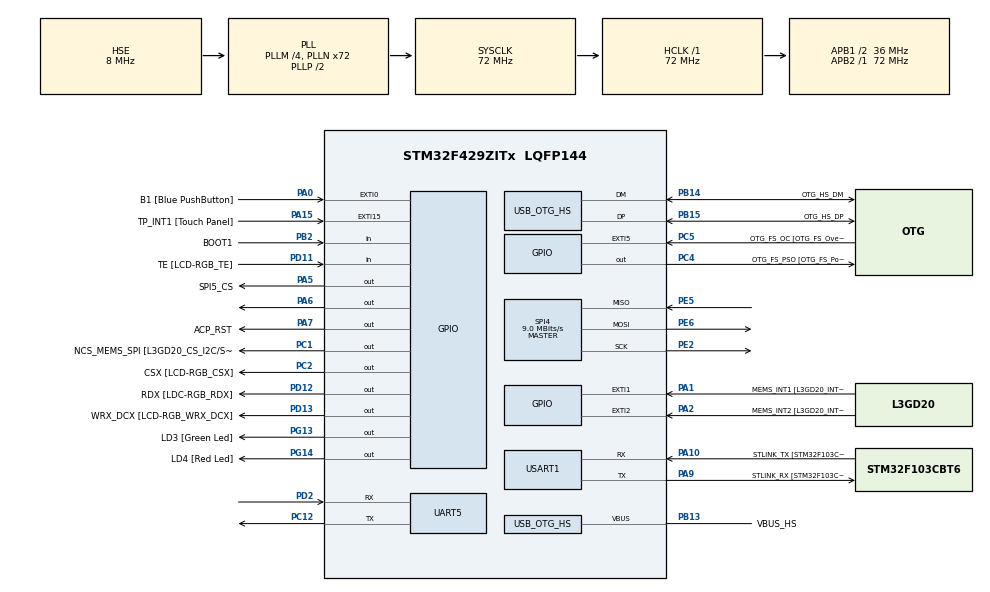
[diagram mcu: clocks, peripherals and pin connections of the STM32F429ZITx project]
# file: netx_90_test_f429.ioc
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Mcu.Family=STM32F4
Mcu.Name=STM32F429ZITx
Mcu.Package=LQFP144
NVIC.OTG_HS_IRQn=true\:0\:0\:false\:false\:true\:true\:true\:true
NVIC.PriorityGroup=NVIC_PRIORITYGROUP_4
NVIC.SPI4_IRQn=true\:0\:0\:false\:false\:true\:true\:true\:true
NVIC.TIM3_IRQn=true\:0\:0\:false\:false\:true\:true\:true\:true
NVIC.TIM6_DAC_IRQn=true\:15\:0\:false\:false\:true\:false\:true\:true
NVIC.TimeBase=TIM6_DAC_IRQn
NVIC.TimeBaseIP=TIM6
NVIC.UART5_IRQn=true\:0\:0\:false\:false\:true\:true\:true\:true
PA0/WKUP.GPIO_Label=B1 [Blue PushButton]
PA0/WKUP.GPIO_ModeDefaultEXTI=GPIO_MODE_EVT_RISING
PA0/WKUP.GPIO_PuPd=GPIO_NOPULL
PA0/WKUP.Signal=GPXTI0
PA1.GPIO_Label=MEMS_INT1 [L3GD20_INT1]
PA1.GPIO_ModeDefaultEXTI=GPIO_MODE_EVT_RISING
PA1.GPIO_PuPd=GPIO_NOPULL
PA1.Signal=GPXTI1
PA10.GPIO_Label=STLINK_TX [STM32F103CBT6_PA2]
PA10.Mode=Asynchronous
PA10.Signal=USART1_RX
PA11.GPIO_Label=R4
PA11.GPIO_Mode=GPIO_MODE_AF_PP
PA11.GPIO_PuPd=GPIO_NOPULL
PA11.GPIO_Speed=GPIO_SPEED_FREQ_LOW
PA11.Signal=LTDC_R4
PA12.GPIO_Label=R5
PA12.GPIO_Mode=GPIO_MODE_AF_PP
PA12.GPIO_PuPd=GPIO_NOPULL
PA12.GPIO_Speed=GPIO_SPEED_FREQ_LOW
PA12.Signal=LTDC_R5
PA13.GPIO_Label=SWDIO
PA13.Mode=Serial_Wire
PA13.Signal=SYS_JTMS-SWDIO
PA14.GPIO_Label=SWCLK
PA14.Mode=Serial_Wire
PA14.Signal=SYS_JTCK-SWCLK
PA15.GPIO_Label=TP_INT1 [Touch Panel]
PA15.GPIO_ModeDefaultEXTI=GPIO_MODE_EVT_RISING
PA15.GPIO_PuPd=GPIO_NOPULL
PA15.Signal=GPXTI15
PA2.GPIO_Label=MEMS_INT2 [L3GD20_INT2]
PA2.GPIO_ModeDefaultEXTI=GPIO_MODE_EVT_RISING
PA2.GPIO_PuPd=GPIO_NOPULL
PA2.Signal=GPXTI2
PA3.GPIO_Label=B5
PA3.GPIO_Mode=GPIO_MODE_AF_PP
PA3.GPIO_PuPd=GPIO_NOPULL
PA3.GPIO_Speed=GPIO_SPEED_FREQ_LOW
PA3.Signal=LTDC_B5
PA4.GPIO_Label=VSYNC
PA4.GPIO_Mode=GPIO_MODE_AF_PP
PA4.GPIO_PuPd=GPIO_NOPULL
PA4.GPIO_Speed=GPIO_SPEED_FREQ_LOW
PA4.Signal=LTDC_VSYNC
PA5.GPIO_Label=SPI5_CS
PA5.Signal=GPIO_Output
PA6.Signal=GPIO_Output
PA7.GPIO_Label=ACP_RST
PA7.GPIO_Mode=GPIO_MODE_OUTPUT_PP
PA7.GPIO_PuPd=GPIO_NOPULL
PA7.GPIO_Speed=GPIO_SPEED_FREQ_LOW
PA7.Signal=GPIO_Output
PA8.GPIO_Label=I2C3_SCL [ACP/RF_SCL]
PA8.GPIO_Mode=GPIO_MODE_AF_OD
PA8.GPIO_Pu=GPIO_PULLUP
PA8.GPIO_PuPd=GPIO_NOPULL
PA8.GPIO_Speed=GPIO_SPEED_FREQ_LOW
PA8.Signal=I2C3_SCL
PA9.GPIO_Label=STLINK_RX [STM32F103CBT6_PA3]
PA9.Mode=Asynchronous
PA9.Signal=USART1_TX
PB0.GPIO_Label=R3
PB0.GPIO_Mode=GPIO_MODE_AF_PP
PB0.GPIO_PuPd=GPIO_NOPULL
PB0.GPIO_Speed=GPIO_SPEED_FREQ_LOW
PB0.Signal=LTDC_R3
PB1.GPIO_Label=R6
PB1.GPIO_Mode=GPIO_MODE_AF_PP
PB1.GPIO_PuPd=GPIO_NOPULL
PB1.GPIO_Speed=GPIO_SPEED_FREQ_LOW
PB1.Signal=LTDC_R6
PB10.GPIO_Label=G4
PB10.GPIO_Mode=GPIO_MODE_AF_PP
PB10.GPIO_PuPd=GPIO_NOPULL
PB10.GPIO_Speed=GPIO_SPEED_FREQ_LOW
PB10.Signal=LTDC_G4
PB11.GPIO_Label=G5
PB11.GPIO_Mode=GPIO_MODE_AF_PP
PB11.GPIO_PuPd=GPIO_NOPULL
PB11.GPIO_Speed=GPIO_SPEED_FREQ_LOW
PB11.Signal=LTDC_G5
PB12.GPIO_Label=OTG_HS_ID
PB12.GPIO_Mode=GPIO_MODE_AF_PP
PB12.GPIO_PuPd=GPIO_NOPULL
PB12.GPIO_Speed=GPIO_SPEED_FREQ_LOW
PB12.Signal=USB_OTG_HS_ID
PB13.GPIO_Label=VBUS_HS
PB13.GPIO_Mode=GPIO_MODE_INPUT
PB13.GPIO_PuPd=GPIO_NOPULL
PB13.Mode=Activate_VBUS_FS
PB13.Signal=USB_OTG_HS_VBUS
PB14.GPIO_Label=OTG_HS_DM
PB14.GPIO_Mode=GPIO_MODE_AF_PP
PB14.GPIO_PuPd=GPIO_NOPULL
PB14.GPIO_Speed=GPIO_SPEED_FREQ_LOW
PB14.Mode=Host_FS
PB14.Signal=USB_OTG_HS_DM
PB15.GPIO_Label=OTG_HS_DP
PB15.GPIO_Mode=GPIO_MODE_AF_PP
PB15.GPIO_PuPd=GPIO_NOPULL
PB15.GPIO_Speed=GPIO_SPEED_FREQ_LOW
PB15.Mode=Host_FS
PB15.Signal=USB_OTG_HS_DP
PB2/BOOT1.GPIO_Label=BOOT1
PB2/BOOT1.GPIO_Mode=GPIO_MODE_INPUT
PB2/BOOT1.GPIO_PuPd=GPIO_NOPULL
PB2/BOOT1.Signal=GPIO_Input
PB5.GPIO_Label=SDCKE1
PB5.GPIO_Mode=GPIO_MODE_AF_PP
PB5.GPIO_PuPd=GPIO_NOPULL
PB5.GPIO_Speed=GPIO_SPEED_FREQ_VERY_HIGH
PB5.Signal=FMC_SDCKE1
PB6.GPIO_Label=SDNE1 [SDRAM_CS]
PB6.GPIO_Mode=GPIO_MODE_AF_PP
PB6.GPIO_PuPd=GPIO_NOPULL
PB6.GPIO_Speed=GPIO_SPEED_FREQ_VERY_HIGH
PB6.Signal=FMC_SDNE1
PB8.GPIO_Label=B6
PB8.GPIO_Mode=GPIO_MODE_AF_PP
PB8.GPIO_PuPd=GPIO_NOPULL
PB8.GPIO_Speed=GPIO_SPEED_FREQ_LOW
PB8.Signal=LTDC_B6
PB9.GPIO_Label=B7
PB9.GPIO_Mode=GPIO_MODE_AF_PP
PB9.GPIO_PuPd=GPIO_NOPULL
PB9.GPIO_Speed=GPIO_SPEED_FREQ_LOW
PB9.Signal=LTDC_B7
PC0.GPIO_Label=SDNWE
PC0.GPIO_Mode=GPIO_MODE_AF_PP
PC0.GPIO_PuPd=GPIO_NOPULL
PC0.GPIO_Speed=GPIO_SPEED_FREQ_VERY_HIGH
PC0.Signal=FMC_SDNWE
PC1.GPIO_Label=NCS_MEMS_SPI [L3GD20_CS_I2C/SPI]
PC1.GPIO_Mode=GPIO_MODE_OUTPUT_PP
PC1.GPIO_PuPd=GPIO_NOPULL
PC1.GPIO_Speed=GPIO_SPEED_FREQ_LOW
PC1.Signal=GPIO_Output
PC10.GPIO_Label=R2
PC10.GPIO_Mode=GPIO_MODE_AF_PP
PC10.GPIO_PuPd=GPIO_NOPULL
PC10.GPIO_Speed=GPIO_SPEED_FREQ_LOW
PC10.Signal=LTDC_R2
PC12.Mode=Asynchronous
PC12.Signal=UART5_TX
PC14/OSC32_IN.GPIO_Label=PC14-OSC32_IN
PC14/OSC32_IN.Signal=RCC_OSC32_IN
PC15/OSC32_OUT.GPIO_Label=PC15-OSC32_OUT
PC15/OSC32_OUT.Signal=RCC_OSC32_OUT
PC2.GPIO_Label=CSX [LCD-RGB_CSX]
PC2.GPIO_Mode=GPIO_MODE_OUTPUT_PP
PC2.GPIO_PuPd=GPIO_NOPULL
PC2.GPIO_Speed=GPIO_SPEED_FREQ_LOW
PC2.Signal=GPIO_Output
PC4.GPIO_Label=OTG_FS_PSO [OTG_FS_PowerSwitchOn]
PC4.GPIO_Mode=GPIO_MODE_OUTPUT_PP
PC4.GPIO_PuPd=GPIO_NOPULL
PC4.GPIO_Speed=GPIO_SPEED_FREQ_LOW
PC4.Signal=GPIO_Output
PC5.GPIO_Label=OTG_FS_OC [OTG_FS_OverCurrent]
PC5.GPIO_ModeDefaultEXTI=GPIO_MODE_EVT_RISING
PC5.Signal=GPXTI5
PC6.GPIO_Label=HSYNC
PC6.GPIO_Mode=GPIO_MODE_AF_PP
PC6.GPIO_PuPd=GPIO_NOPULL
PC6.GPIO_Speed=GPIO_SPEED_FREQ_LOW
PC6.Signal=LTDC_HSYNC
PC7.GPIO_Label=G6
PC7.GPIO_Mode=GPIO_MODE_AF_PP
PC7.GPIO_PuPd=GPIO_NOPULL
PC7.GPIO_Speed=GPIO_SPEED_FREQ_LOW
PC7.Signal=LTDC_G6
PC9.GPIO_Label=I2C3_SDA [ACP/RF_SDA]
PC9.GPIO_Mode=GPIO_MODE_AF_OD
PC9.GPIO_Pu=GPIO_PULLUP
PC9.GPIO_PuPd=GPIO_NOPULL
PC9.GPIO_Speed=GPIO_SPEED_FREQ_LOW
PC9.Signal=I2C3_SDA
PD0.GPIO_Label=D2
PD0.GPIO_Mode=GPIO_MODE_AF_PP
PD0.GPIO_PuPd=GPIO_NOPULL
PD0.GPIO_Speed=GPIO_SPEED_FREQ_VERY_HIGH
PD0.Signal=FMC_D2_DA2
PD1.GPIO_Label=D3
PD1.GPIO_Mode=GPIO_MODE_AF_PP
PD1.GPIO_PuPd=GPIO_NOPULL
PD1.GPIO_Speed=GPIO_SPEED_FREQ_VERY_HIGH
PD1.Signal=FMC_D3_DA3
PD10.GPIO_Label=D15
PD10.GPIO_Mode=GPIO_MODE_AF_PP
PD10.GPIO_PuPd=GPIO_NOPULL
PD10.GPIO_Speed=GPIO_SPEED_FREQ_VERY_HIGH
PD10.Signal=FMC_D15_DA15
PD11.GPIO_Label=TE [LCD-RGB_TE]
PD11.GPIO_Mode=GPIO_MODE_INPUT
PD11.GPIO_PuPd=GPIO_NOPULL
PD11.Signal=GPIO_Input
PD12.GPIO_Label=RDX [LDC-RGB_RDX]
PD12.GPIO_Mode=GPIO_MODE_OUTPUT_PP
PD12.GPIO_PuPd=GPIO_NOPULL
PD12.GPIO_Speed=GPIO_SPEED_FREQ_LOW
PD12.Signal=GPIO_Output
PD13.GPIO_Label=WRX_DCX [LCD-RGB_WRX_DCX]
PD13.GPIO_Mode=GPIO_MODE_OUTPUT_PP
PD13.GPIO_PuPd=GPIO_NOPULL
PD13.GPIO_Speed=GPIO_SPEED_FREQ_LOW
PD13.Signal=GPIO_Output
PD14.GPIO_Label=D0
PD14.GPIO_Mode=GPIO_MODE_AF_PP
PD14.GPIO_PuPd=GPIO_NOPULL
PD14.GPIO_Speed=GPIO_SPEED_FREQ_VERY_HIGH
PD14.Signal=FMC_D0_DA0
PD15.GPIO_Label=D1
PD15.GPIO_Mode=GPIO_MODE_AF_PP
PD15.GPIO_PuPd=GPIO_NOPULL
PD15.GPIO_Speed=GPIO_SPEED_FREQ_VERY_HIGH
PD15.Signal=FMC_D1_DA1
PD2.Mode=Asynchronous
PD2.Signal=UART5_RX
PD3.GPIO_Label=G7
PD3.GPIO_Mode=GPIO_MODE_AF_PP
PD3.GPIO_PuPd=GPIO_NOPULL
PD3.GPIO_Speed=GPIO_SPEED_FREQ_LOW
PD3.Signal=LTDC_G7
PD6.GPIO_Label=B2
PD6.GPIO_Mode=GPIO_MODE_AF_PP
PD6.GPIO_PuPd=GPIO_NOPULL
PD6.GPIO_Speed=GPIO_SPEED_FREQ_LOW
PD6.Signal=LTDC_B2
PD8.GPIO_Label=D13
PD8.GPIO_Mode=GPIO_MODE_AF_PP
PD8.GPIO_PuPd=GPIO_NOPULL
PD8.GPIO_Speed=GPIO_SPEED_FREQ_VERY_HIGH
PD8.Signal=FMC_D13_DA13
PD9.GPIO_Label=D14
PD9.GPIO_Mode=GPIO_MODE_AF_PP
PD9.GPIO_PuPd=GPIO_NOPULL
PD9.GPIO_Speed=GPIO_SPEED_FREQ_VERY_HIGH
PD9.Signal=FMC_D14_DA14
PE0.GPIO_Label=NBL0 [SDRAM_LDQM]
PE0.GPIO_Mode=GPIO_MODE_AF_PP
PE0.GPIO_PuPd=GPIO_NOPULL
PE0.GPIO_Speed=GPIO_SPEED_FREQ_VERY_HIGH
PE0.Signal=FMC_NBL0
PE1.GPIO_Label=NBL1 [SDRAM_UDQM]
PE1.GPIO_Mode=GPIO_MODE_AF_PP
PE1.GPIO_PuPd=GPIO_NOPULL
PE1.GPIO_Speed=GPIO_SPEED_FREQ_VERY_HIGH
PE1.Signal=FMC_NBL1
PE10.GPIO_Label=D7
PE10.GPIO_Mode=GPIO_MODE_AF_PP
PE10.GPIO_PuPd=GPIO_NOPULL
PE10.GPIO_Speed=GPIO_SPEED_FREQ_VERY_HIGH
PE10.Signal=FMC_D7_DA7
PE11.GPIO_Label=D8
PE11.GPIO_Mode=GPIO_MODE_AF_PP
PE11.GPIO_PuPd=GPIO_NOPULL
PE11.GPIO_Speed=GPIO_SPEED_FREQ_VERY_HIGH
PE11.Signal=FMC_D8_DA8
PE12.GPIO_Label=D9
PE12.GPIO_Mode=GPIO_MODE_AF_PP
PE12.GPIO_PuPd=GPIO_NOPULL
PE12.GPIO_Speed=GPIO_SPEED_FREQ_VERY_HIGH
PE12.Signal=FMC_D9_DA9
PE13.GPIO_Label=D10
PE13.GPIO_Mode=GPIO_MODE_AF_PP
PE13.GPIO_PuPd=GPIO_NOPULL
PE13.GPIO_Speed=GPIO_SPEED_FREQ_VERY_HIGH
PE13.Signal=FMC_D10_DA10
PE14.GPIO_Label=D11
PE14.GPIO_Mode=GPIO_MODE_AF_PP
PE14.GPIO_PuPd=GPIO_NOPULL
PE14.GPIO_Speed=GPIO_SPEED_FREQ_VERY_HIGH
PE14.Signal=FMC_D11_DA11
PE15.GPIO_Label=D12
PE15.GPIO_Mode=GPIO_MODE_AF_PP
PE15.GPIO_PuPd=GPIO_NOPULL
PE15.GPIO_Speed=GPIO_SPEED_FREQ_VERY_HIGH
PE15.Signal=FMC_D12_DA12
PE2.Mode=Full_Duplex_Master
PE2.Signal=SPI4_SCK
PE5.Mode=Full_Duplex_Master
PE5.Signal=SPI4_MISO
PE6.Mode=Full_Duplex_Master
PE6.Signal=SPI4_MOSI
PE7.GPIO_Label=D4
PE7.GPIO_Mode=GPIO_MODE_AF_PP
PE7.GPIO_PuPd=GPIO_NOPULL
PE7.GPIO_Speed=GPIO_SPEED_FREQ_VERY_HIGH
PE7.Signal=FMC_D4_DA4
PE8.GPIO_Label=D5
PE8.GPIO_Mode=GPIO_MODE_AF_PP
PE8.GPIO_PuPd=GPIO_NOPULL
PE8.GPIO_Speed=GPIO_SPEED_FREQ_VERY_HIGH
PE8.Signal=FMC_D5_DA5
PE9.GPIO_Label=D6
PE9.GPIO_Mode=GPIO_MODE_AF_PP
PE9.GPIO_PuPd=GPIO_NOPULL
PE9.GPIO_Speed=GPIO_SPEED_FREQ_VERY_HIGH
PE9.Signal=FMC_D6_DA6
PF0.GPIO_Label=A0
PF0.GPIO_Mode=GPIO_MODE_AF_PP
PF0.GPIO_PuPd=GPIO_NOPULL
PF0.GPIO_Speed=GPIO_SPEED_FREQ_VERY_HIGH
PF0.Signal=FMC_A0
PF1.GPIO_Label=A1
PF1.GPIO_Mode=GPIO_MODE_AF_PP
PF1.GPIO_PuPd=GPIO_NOPULL
PF1.GPIO_Speed=GPIO_SPEED_FREQ_VERY_HIGH
PF1.Signal=FMC_A1
PF10.GPIO_Label=ENABLE [LCD-RGB_ENABLE]
PF10.GPIO_Mode=GPIO_MODE_AF_PP
PF10.GPIO_PuPd=GPIO_NOPULL
PF10.GPIO_Speed=GPIO_SPEED_FREQ_LOW
PF10.Signal=LTDC_DE
PF11.GPIO_Label=SDNRAS
PF11.GPIO_Mode=GPIO_MODE_AF_PP
PF11.GPIO_PuPd=GPIO_NOPULL
PF11.GPIO_Speed=GPIO_SPEED_FREQ_VERY_HIGH
PF11.Signal=FMC_SDNRAS
PF12.GPIO_Label=A6
PF12.GPIO_Mode=GPIO_MODE_AF_PP
PF12.GPIO_PuPd=GPIO_NOPULL
PF12.GPIO_Speed=GPIO_SPEED_FREQ_VERY_HIGH
PF12.Signal=FMC_A6
PF13.GPIO_Label=A7
PF13.GPIO_Mode=GPIO_MODE_AF_PP
PF13.GPIO_PuPd=GPIO_NOPULL
PF13.GPIO_Speed=GPIO_SPEED_FREQ_VERY_HIGH
PF13.Signal=FMC_A7
PF14.GPIO_Label=A8
PF14.GPIO_Mode=GPIO_MODE_AF_PP
PF14.GPIO_PuPd=GPIO_NOPULL
PF14.GPIO_Speed=GPIO_SPEED_FREQ_VERY_HIGH
PF14.Signal=FMC_A8
PF15.GPIO_Label=A9
PF15.GPIO_Mode=GPIO_MODE_AF_PP
PF15.GPIO_PuPd=GPIO_NOPULL
PF15.GPIO_Speed=GPIO_SPEED_FREQ_VERY_HIGH
PF15.Signal=FMC_A9
PF2.GPIO_Label=A2
PF2.GPIO_Mode=GPIO_MODE_AF_PP
PF2.GPIO_PuPd=GPIO_NOPULL
PF2.GPIO_Speed=GPIO_SPEED_FREQ_VERY_HIGH
PF2.Signal=FMC_A2
PF3.GPIO_Label=A3
PF3.GPIO_Mode=GPIO_MODE_AF_PP
PF3.GPIO_PuPd=GPIO_NOPULL
PF3.GPIO_Speed=GPIO_SPEED_FREQ_VERY_HIGH
PF3.Signal=FMC_A3
PF4.GPIO_Label=A4
PF4.GPIO_Mode=GPIO_MODE_AF_PP
PF4.GPIO_PuPd=GPIO_NOPULL
PF4.GPIO_Speed=GPIO_SPEED_FREQ_VERY_HIGH
PF4.Signal=FMC_A4
PF5.GPIO_Label=A5
PF5.GPIO_Mode=GPIO_MODE_AF_PP
PF5.GPIO_PuPd=GPIO_NOPULL
PF5.GPIO_Speed=GPIO_SPEED_FREQ_VERY_HIGH
PF5.Signal=FMC_A5
PF7.GPIO_Label=SPI5_SCK [L3GD20_SCL/SPC]
PF7.GPIO_Mode=GPIO_MODE_AF_PP
PF7.GPIO_PuPd=GPIO_NOPULL
PF7.GPIO_Speed=GPIO_SPEED_FREQ_LOW
PF7.Signal=SPI5_SCK
PF8.GPIO_Label=SPI5_MISO [L3GD20_SDO]
PF8.GPIO_Mode=GPIO_MODE_AF_PP
PF8.GPIO_PuPd=GPIO_NOPULL
PF8.GPIO_Speed=GPIO_SPEED_FREQ_LOW
PF8.Signal=SPI5_MISO
PF9.GPIO_Label=SPI5_MOSI [L3GD20_SDA/SDI/SDO]
PF9.GPIO_Mode=GPIO_MODE_AF_PP
PF9.GPIO_PuPd=GPIO_NOPULL
PF9.GPIO_Speed=GPIO_SPEED_FREQ_LOW
PF9.Signal=SPI5_MOSI
PG0.GPIO_Label=A10
PG0.GPIO_Mode=GPIO_MODE_AF_PP
PG0.GPIO_PuPd=GPIO_NOPULL
PG0.GPIO_Speed=GPIO_SPEED_FREQ_VERY_HIGH
PG0.Signal=FMC_A10
PG1.GPIO_Label=A11
PG1.GPIO_Mode=GPIO_MODE_AF_PP
PG1.GPIO_PuPd=GPIO_NOPULL
PG1.GPIO_Speed=GPIO_SPEED_FREQ_VERY_HIGH
PG1.Signal=FMC_A11
PG10.GPIO_Label=G3
PG10.GPIO_Mode=GPIO_MODE_AF_PP
PG10.GPIO_PuPd=GPIO_NOPULL
PG10.GPIO_Speed=GPIO_SPEED_FREQ_LOW
PG10.Signal=LTDC_G3
PG11.GPIO_Label=B3
PG11.GPIO_Mode=GPIO_MODE_AF_PP
PG11.GPIO_PuPd=GPIO_NOPULL
PG11.GPIO_Speed=GPIO_SPEED_FREQ_LOW
PG11.Signal=LTDC_B3
PG12.GPIO_Label=B4
PG12.GPIO_Mode=GPIO_MODE_AF_PP
PG12.GPIO_PuPd=GPIO_NOPULL
PG12.GPIO_Speed=GPIO_SPEED_FREQ_LOW
PG12.Signal=LTDC_B4
PG13.GPIO_Label=LD3 [Green Led]
PG13.GPIO_Mode=GPIO_MODE_OUTPUT_PP
PG13.GPIO_PuPd=GPIO_NOPULL
PG13.GPIO_Speed=GPIO_SPEED_FREQ_LOW
PG13.Signal=GPIO_Output
PG14.GPIO_Label=LD4 [Red Led]
PG14.GPIO_Mode=GPIO_MODE_OUTPUT_PP
PG14.GPIO_PuPd=GPIO_NOPULL
PG14.GPIO_Speed=GPIO_SPEED_FREQ_LOW
PG14.Signal=GPIO_Output
PG15.GPIO_Label=SDNCAS
PG15.GPIO_Mode=GPIO_MODE_AF_PP
PG15.GPIO_PuPd=GPIO_NOPULL
PG15.GPIO_Speed=GPIO_SPEED_FREQ_VERY_HIGH
PG15.Signal=FMC_SDNCAS
PG4.GPIO_Label=BA0
PG4.GPIO_Mode=GPIO_MODE_AF_PP
PG4.GPIO_PuPd=GPIO_NOPULL
PG4.GPIO_Speed=GPIO_SPEED_FREQ_VERY_HIGH
PG4.Signal=FMC_A14_BA0
PG5.GPIO_Label=BA1
PG5.GPIO_Mode=GPIO_MODE_AF_PP
PG5.GPIO_PuPd=GPIO_NOPULL
PG5.GPIO_Speed=GPIO_SPEED_FREQ_VERY_HIGH
PG5.Signal=FMC_A15_BA1
PG6.GPIO_Label=R7
PG6.GPIO_Mode=GPIO_MODE_AF_PP
PG6.GPIO_PuPd=GPIO_NOPULL
PG6.GPIO_Speed=GPIO_SPEED_FREQ_LOW
PG6.Signal=LTDC_R7
PG7.GPIO_Label=DOTCLK [LCT-RGB_DOTCLK]
PG7.GPIO_Mode=GPIO_MODE_AF_PP
PG7.GPIO_PuPd=GPIO_NOPULL
PG7.GPIO_Speed=GPIO_SPEED_FREQ_LOW
PG7.Signal=LTDC_CLK
PG8.GPIO_Label=SDCLK
PG8.GPIO_Mode=GPIO_MODE_AF_PP
PG8.GPIO_PuPd=GPIO_NOPULL
PG8.GPIO_Speed=GPIO_SPEED_FREQ_VERY_HIGH
PG8.Signal=FMC_SDCLK
PH0/OSC_IN.GPIO_Label=PH0-OSC_IN
PH0/OSC_IN.Mode=HSE-External-Oscillator
PH0/OSC_IN.Signal=RCC_OSC_IN
PH1/OSC_OUT.GPIO_Label=PH1-OSC_OUT
PH1/OSC_OUT.Mode=HSE-External-Oscillator
PH1/OSC_OUT.Signal=RCC_OSC_OUT
ProjectManager.HeapSize=0x200
ProjectManager.StackSize=0x400
ProjectManager.TargetToolchain=STM32CubeIDE
RCC.48MHZClocksFreq_Value=48000000
RCC.AHBFreq_Value=72000000
RCC.APB1CLKDivider=RCC_HCLK_DIV2
RCC.APB1Freq_Value=36000000
RCC.APB1TimFreq_Value=72000000
RCC.APB2Freq_Value=72000000
RCC.APB2TimFreq_Value=72000000
RCC.CortexFreq_Value=72000000
RCC.HCLKFreq_Value=72000000
RCC.HSE_VALUE=8000000
RCC.HSI_VALUE=16000000
RCC.LSE_VALUE=32768
RCC.PLLM=4
RCC.PLLN=72
RCC.PLLQ=3
RCC.PLLSAIN=50
RCC.SYSCLKFreq_VALUE=72000000
RCC.SYSCLKSource=RCC_SYSCLKSOURCE_PLLCLK
RCC.VCOOutputFreq_Value=144000000
SH.FMC_A0.0=FMC_A0
SH.FMC_A1.0=FMC_A1
SH.FMC_A10.0=FMC_A10
SH.FMC_A11.0=FMC_A11
SH.FMC_A14_BA0.0=FMC_BA0
SH.FMC_A15_BA1.0=FMC_BA1
SH.FMC_A2.0=FMC_A2
SH.FMC_A3.0=FMC_A3
SH.FMC_A4.0=FMC_A4
SH.FMC_A5.0=FMC_A5
SH.FMC_A6.0=FMC_A6
SH.FMC_A7.0=FMC_A7
SH.FMC_A8.0=FMC_A8
SH.FMC_A9.0=FMC_A9
SH.FMC_D0_DA0.0=FMC_D0
SH.FMC_D10_DA10.0=FMC_D10
SH.FMC_D11_DA11.0=FMC_D11
SH.FMC_D12_DA12.0=FMC_D12
SH.FMC_D13_DA13.0=FMC_D13
SH.FMC_D14_DA14.0=FMC_D14
SH.FMC_D15_DA15.0=FMC_D15
SH.FMC_D1_DA1.0=FMC_D1
SH.FMC_D2_DA2.0=FMC_D2
SH.FMC_D3_DA3.0=FMC_D3
SH.FMC_D4_DA4.0=FMC_D4
SH.FMC_D5_DA5.0=FMC_D5
SH.FMC_D6_DA6.0=FMC_D6
SH.FMC_D7_DA7.0=FMC_D7
SH.FMC_D8_DA8.0=FMC_D8
SH.FMC_D9_DA9.0=FMC_D9
SH.FMC_NBL0.0=FMC_NBL0
SH.FMC_NBL1.0=FMC_NBL1
SH.FMC_SDCLK.0=FMC_SDCLK
SH.FMC_SDNCAS.0=FMC_SDNCAS
SH.FMC_SDNRAS.0=FMC_SDNRAS
SH.FMC_SDNWE.0=FMC_SDNWE
SPI4.BaudRatePrescaler=SPI_BAUDRATEPRESCALER_8
SPI4.CLKPhase=SPI_PHASE_2EDGE
SPI4.CLKPolarity=SPI_POLARITY_HIGH
SPI4.CalculateBaudRate=9.0 MBits/s
SPI4.Direction=SPI_DIRECTION_2LINES
SPI4.Mode=SPI_MODE_MASTER
SPI4.VirtualType=VM_MASTER
TIM3.Period=1000-1
TIM3.Prescaler=200-1
UART5.VirtualMode=Asynchronous
USART1.VirtualMode=VM_ASYNC
USB_HOST.BSP.number=1
USB_HOST.USBH_HandleTypeDef-CDC_HS=hUsbHostHS
USB_HOST.VirtualModeHS=Cdc
USB_HOST0.BSP.STBoard=false
USB_HOST0.BSP.api=UnknownBspDriver
USB_HOST0.BSP.instance=PC4
USB_HOST0.BSP.ip=GPIO
USB_HOST0.BSP.mode=Output
USB_HOST0.BSP.name=Drive_VBUS_HS
USB_HOST0.BSP.solution=PC4
USB_OTG_HS.VirtualMode-Host_FS=Host_FS
VP_SYS_VS_tim6.Mode=TIM6
VP_TIM1_VS_ClockSourceINT.Mode=Internal
VP_TIM3_VS_ClockSourceINT.Mode=Internal
VP_USB_HOST_VS_USB_HOST_CDC_HS.Mode=CDC_HS
board=STM32F429I-DISC1

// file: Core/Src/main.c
/* USER CODE BEGIN Header */
/**
 * Louis 2025-07-22 15:54:47 -> 25-10-27 122009 -> 25-11-12
 * VAT Explicit custom message 통신 - OK
 * Version : stm32f429_disco_VAT_EDS_0.2.0
  ******************************************************************************
  * @file           : main.c
  * @brief          : Main program body
  ******************************************************************************
  * @attention
  *
  * Copyright (c) 2025 STMicroelectronics.
  * All rights reserved.
  *
  * This software is licensed under terms that can be found in the LICENSE file
  * in the root directory of this software component.
  * If no LICENSE file comes with this software, it is provided AS-IS.
  *
  ******************************************************************************
  */
/* USER CODE END Header */
#include "main.h"
#include "usb_host.h"

/* USER CODE BEGIN Includes */
#include <stdio.h>
#include <stdbool.h>
#include <string.h>
#include "cifXToolkit.h"
#include "SerialDPMInterface.h"
#include "cifXErrors.h"
#include "App_DemoApplication.h"
#include "Hil_DualPortMemory.h"      // COS flags 정의

/* ========== VAT TEST INTEGRATION - 추가 시작 ========== */
#include "vat_devicenet_test.h"
#include "devicenet_master_info.h"
#include "AppDNS_DemoApplication.h"  // DeviceNet 스택 초기화 함수
#include "App_VAT_Parameters.h"      // VAT 파라미터 매니저
#include "App_VAT_Diagnostic.h"      // VAT 진단 매니저
#include "App_VAT_ExplicitHandler.h" // VAT Explicit 핸들러
/* ========== VAT TEST INTEGRATION - 추가 끝 ========== */
/* USER CODE END Includes */

/* USER CODE BEGIN PTD */
//#define UART_RX_BUFFER_SIZE 256
//typedef struct {
//    uint8_t buffer[UART_RX_BUFFER_SIZE];
//    volatile uint16_t head;
//    volatile uint16_t tail;
//} RingBuffer;

/* USER CODE END PTD */

SPI_HandleTypeDef hspi4;

TIM_HandleTypeDef htim1;
TIM_HandleTypeDef htim3;

UART_HandleTypeDef huart5;
UART_HandleTypeDef huart1;

/* USER CODE BEGIN PV */
// 전역 영역에 선언
volatile char g_szLastCookie[5] = {0};   // 외부 모니터링 가능

/* ========== DeviceNet 스택 초기화 - extern 선언 ========== */
extern PROTOCOL_DESCRIPTOR_T g_tRealtimeProtocolHandlers;  // AppDNS_DemoApplication.c에서 정의
extern APP_DATA_T g_tAppData;                              // App_SystemPackets.c에서 정의
extern APP_DNS_DATA_T g_tAppDnsData;                       // AppDNS_DemoApplicationFunctions.c에서 정의
extern uint32_t App_AllChannels_PacketHandler(APP_DATA_T* ptAppData);  // App_DemoApplication.c
/* ========== extern 선언 끝 ========== */

uint8_t rx_data[10] = {0};
uint32_t delayCount =0;

uint8_t rxBuffer[64];
uint8_t rxByte;
uint8_t txMessage[] = "STM32 UART5 says hello to netX90!\r\n";
volatile uint8_t rxReady = 0;

static UART_HandleTypeDef *huart_ring;
static RingBuffer rx_ring;

static uint8_t rx_temp; // 수신용 임시 바이트 저장

uint8_t line[100];

/** DIP switch validation variables */
volatile uint8_t g_DipSwitchData[5] = {0};  // Validated DIP switch data: "1010" + null terminator
volatile uint8_t g_bDipDataValid = 0;       // Flag indicating valid DIP data received

/* VAT 시뮬레이션 상태 */
typedef struct {
    int16_t current_pressure;
    int16_t current_position;
    uint8_t device_status;
    uint8_t exception_status;
} VAT_SIM_STATE_T;

static VAT_SIM_STATE_T g_tVatSimState = {0};

/* ========== VAT TEST INTEGRATION - 추가 시작 ========== */
/**
 * VAT 테스트 컨텍스트 전역 변수
 * - Live Expression으로 모니터링 가능
 * - 디버거에서 실시간 데이터 확인
 */
VAT_TEST_CONTEXT_T g_tVatContext;

/**
 * VAT 테스트 모드 선택
 * 0 = 기본 App_CifXApplicationDemo 실행 (기존 동작)
 * 1 = VAT Basic Pressure Control Test
 * 2 = VAT Full Calibration Test
 * 3 = VAT Continuous Monitoring (100 cycles)
 */
//volatile uint8_t g_VatTestMode = 1;  // 기본값: Basic Pressure Control
// volatile uint8_t g_VatTestMode = 3;  // 기본값: Basic Pressure Control
volatile uint8_t g_VatTestMode = 4;  // 기본값: Basic Pressure Control

/**
 * VAT 테스트 활성화 플래그
 * true = VAT 테스트 실행
 * false = 기존 App_CifXApplicationDemo 실행
 */
volatile bool g_bEnableVatTest = true; // false; //
/* ========== VAT TEST INTEGRATION - 추가 끝 ========== */

/* USER CODE END PV */

void SystemClock_Config(void);
static void MX_GPIO_Init(void);
static void MX_TIM1_Init(void);
static void MX_USART1_UART_Init(void);
static void MX_TIM3_Init(void);
static void MX_SPI4_Init(void);
static void MX_UART5_Init(void);
void MX_USB_HOST_Process(void);

/* USER CODE BEGIN PFP */
static int32_t PreCommunicateWithSPI0(void);
static uint8_t ExtractDipSwitchData(const uint8_t *line, uint8_t *dipData);
static uint8_t ValidateDipSwitchData(const uint8_t *currentLine);

/* ========== VAT TEST INTEGRATION - 추가 시작 ========== */
static void PrintDeviceInformation(CIFXHANDLE hDriver, CIFXHANDLE hChannel);
static void PrintDeviceNetStatus(APP_DATA_T* ptAppData);  // ⭐ DeviceNet 상태 디버깅
static void VAT_InitializeTest(void);
static void VAT_RunTest(CIFXHANDLE hChannel);
/* ========== VAT TEST INTEGRATION - 추가 끝 ========== */
/* USER CODE END PFP */

/* USER CODE BEGIN 0 */

/**
 * @brief Redirect printf to UART5
 * @param ch Character to send
 * @return Character sent
 *
 * 최적화: 짧은 타임아웃으로 속도 개선
 * 115200 baud: 1 byte = ~87 μs, 10ms면 충분
 */
int __io_putchar(int ch)
{
    /* Send character via UART5 with 10ms timeout */
    // HAL_UART_Transmit(&huart5, (uint8_t *)&ch, 1, 10);
    HAL_UART_Transmit(&huart1, (uint8_t *)&ch, 1, 10);
    return ch;
}

static bool isCookieAvailable(PDEVICEINSTANCE ptDevInstance, uint32_t ulTimeoutInMs)
{
  bool fCookieAvailable = false;
  char szCookie[5];
  uint32_t starttime;
  uint32_t difftime = 0;

  starttime = OS_GetMilliSecCounter();

  while(false == fCookieAvailable && difftime < ulTimeoutInMs)
  {
    OS_Memset(szCookie, 0, sizeof(szCookie));

    HWIF_READN(ptDevInstance, szCookie, ptDevInstance->pbDPM, 4);

    // 전역 변수로 복사 (null termination 포함) Louis
//    szCookie[4] = '\0';  // 안전하게 null-terminated 보장
    OS_Memcpy((void*)g_szLastCookie, szCookie, sizeof(g_szLastCookie));

    /** on DPM cards we need to check the for a valid cookie */
    if((0 == OS_Strcmp(szCookie, CIFX_DPMSIGNATURE_BSL_STR)) || (0 == OS_Strcmp(szCookie, CIFX_DPMSIGNATURE_FW_STR)))
    {
      /** We have a firmware or bootloader running, so we assume it is a flash based device */
      /** NOTE: If the driver is restarted and a RAM based FW was downloaded before this
       will result in the device being handled as flash based.
       Currently there is no way to detect this */
      fCookieAvailable = true;
    }
    else
    {
      fCookieAvailable = false;
      difftime = OS_GetMilliSecCounter() - starttime;
    }
  }

  if(false == fCookieAvailable)
  {
    printf("DPM cookie not available since %u milliseconds\r\n", (unsigned int) ulTimeoutInMs);
  }

  return fCookieAvailable;
}

static int32_t InitializeToolkit()
{
  int32_t lRet = CIFX_NO_ERROR;

  lRet = cifXTKitInit();

  if(CIFX_NO_ERROR == lRet)
  {
    PDEVICEINSTANCE ptDevInstance = (PDEVICEINSTANCE) OS_Memalloc(sizeof(*ptDevInstance));
    OS_Memset(ptDevInstance, 0, sizeof(*ptDevInstance));

    /** Set trace level of toolkit */
    g_ulTraceLevel = TRACE_LEVEL_ERROR |
    TRACE_LEVEL_WARNING |
    TRACE_LEVEL_INFO |
    TRACE_LEVEL_DEBUG;

    /** Insert the basic device information into the DeviceInstance structure
     for the toolkit.
     NOTE: The irq number are for information use only, so we skip them here.
     Interrupt is currently not supported and ignored, so we don't need to set it */
    ptDevInstance->fPCICard = 0;
    ptDevInstance->pvOSDependent = ptDevInstance;
    ptDevInstance->ulDPMSize = 0x8000;           // 32K
    OS_Strncpy(ptDevInstance->szName, "cifX0", sizeof(ptDevInstance->szName));

    /** we know here that netX firmware is flash based, therefore we check if it starts up
     ** by comparing cookie at DPM address 0x00 is valid.*/

    do
    {
      SerialDPM_Init(ptDevInstance);
    } while(false == isCookieAvailable(ptDevInstance, 100));

    /* Add the device to the toolkits handled device list */
    lRet = cifXTKitAddDevice(ptDevInstance);

    /** If it succeeded do device tests */
    if(CIFX_NO_ERROR != lRet)
    {
      /** Uninitialize Toolkit, this will remove all handled boards from the toolkit and
       deallocate the device instance */
      cifXTKitDeinit();
    }
  }

  return lRet;
}

/* ========== VAT TEST INTEGRATION - 함수 구현 시작 ========== */

/**
 * @brief DeviceNet Stack 상태 출력 (디버깅용)
 *
 * @param ptAppData  Application data structure
 *
 * Stack 초기화 후 상태를 확인하여 Explicit 메시징 준비 상태를 점검
 */
static void PrintDeviceNetStatus(APP_DATA_T* ptAppData)
{
    CHANNEL_INFORMATION tInfo;
    int32_t lRet;

    // Get channel information
    lRet = xChannelInfo(ptAppData->aptChannels[DNS_DEMO_CHANNEL_INDEX]->hChannel,
                        sizeof(CHANNEL_INFORMATION),
                        &tInfo);

    if (lRet != CIFX_NO_ERROR) {
        printf("[ERROR] Failed to get channel info: 0x%08X\r\n", (unsigned int)lRet);
        return;
    }

    // Print status banner
    printf("\r\n");
    printf("=============================================\r\n");
    printf("  DeviceNet Stack Status\r\n");
    printf("=============================================\r\n");

    // Channel READY status
    printf("Channel READY:     %s\r\n",
        (tInfo.ulDeviceCOSFlags & HIL_COMM_COS_READY) ? "[OK] YES" : "[FAIL] NO");

    // BUS ON status
    printf("BUS ON:            %s\r\n",
        (tInfo.ulDeviceCOSFlags & HIL_COMM_COS_BUS_ON) ? "[OK] YES" : "[FAIL] NO");

    // Communication state
    printf("Comm State:        %s\r\n",
        (tInfo.ulDeviceCOSFlags & HIL_COMM_COS_RUN) ? "[OK] RUN" : "[WARN] STOP");

    // Node configuration
    printf("\r\n--- Configuration ---\r\n");
    printf("Node ID:           %d\r\n", g_tAppDnsData.bNodeIdValue);
    printf("Baud Rate:         ");
    switch (g_tAppDnsData.bBaudRateValue) {
        case 0: printf("125 kB/s\r\n"); break;
        case 1: printf("250 kB/s\r\n"); break;
        case 2: printf("500 kB/s\r\n"); break;
        default: printf("Unknown (%d)\r\n", g_tAppDnsData.bBaudRateValue); break;
    }

    // Device information
    printf("\r\n--- Device Info ---\r\n");
    printf("Device Number:     %u\r\n", (unsigned int)tInfo.ulDeviceNumber);
    printf("Serial Number:     %u\r\n", (unsigned int)tInfo.ulSerialNumber);
    printf("Firmware:          %u.%u.%u build %u\r\n",
        (unsigned int)tInfo.usFWMajor,
        (unsigned int)tInfo.usFWMinor,
        (unsigned int)tInfo.usFWRevision,
        (unsigned int)tInfo.usFWBuild);

    // Error information
    printf("\r\n--- Error Status ---\r\n");
    if (tInfo.ulDeviceCOSFlags & HIL_COMM_COS_CONFIG_LOCKED) {
        printf("Config Locked:     [WARN] YES (cannot reconfigure)\r\n");
    } else {
        printf("Config Locked:     [OK] NO\r\n");
    }

    printf("=============================================\r\n\r\n");

    // Explicit message readiness check
    if ((tInfo.ulDeviceCOSFlags & HIL_COMM_COS_READY) &&
        (tInfo.ulDeviceCOSFlags & HIL_COMM_COS_BUS_ON)) {
        printf("✅ Stack is READY for Explicit Messaging\r\n\r\n");
    } else {
        printf("❌ Stack is NOT READY for Explicit Messaging\r\n");
        printf("   Please check Channel READY and BUS ON status\r\n\r\n");
    }
}

/**
 * @brief 디바이스 정보 출력
 *
 * @param hDriver   cifX 드라이버 핸들
 * @param hChannel  cifX 채널 핸들
 *
 * 드라이버, 보드, 채널 정보를 조회하여 출력
 */
static void PrintDeviceInformation(CIFXHANDLE hDriver, CIFXHANDLE hChannel)
{
    int32_t lRet = CIFX_NO_ERROR;

    printf("\r\n");
    printf("========================================\r\n");
    printf(" Device Information\r\n");
    printf("========================================\r\n");

    /* 1. 드라이버 정보 */
    DRIVER_INFORMATION tDriverInfo;
    lRet = xDriverGetInformation(hDriver, sizeof(DRIVER_INFORMATION), &tDriverInfo);
    if(lRet == CIFX_NO_ERROR)
    {
        printf("\r\n[Driver Information]\r\n");
        printf("  Driver Version:  %s\r\n", tDriverInfo.abDriverVersion);
        printf("  Board Count:     %lu\r\n", tDriverInfo.ulBoardCnt);
    }
    else
    {
        printf("\r\n[Driver Information] ERROR: 0x%08X\r\n", (unsigned int)lRet);
    }

    /* 2. 보드 정보 */
    BOARD_INFORMATION tBoardInfo;
    lRet = xDriverEnumBoards(hDriver, 0, sizeof(BOARD_INFORMATION), &tBoardInfo);
    if(lRet == CIFX_NO_ERROR)
    {
        printf("\r\n[Board Information]\r\n");
        printf("  Board Name:      %s\r\n", tBoardInfo.abBoardName);
        printf("  Board Alias:     %s\r\n", tBoardInfo.abBoardAlias);
        printf("  Board ID:        0x%08lX\r\n", tBoardInfo.ulBoardID);
        printf("  Device Number:   %lu\r\n", tBoardInfo.tSystemInfo.ulDeviceNumber);
        printf("  Serial Number:   %lu\r\n", tBoardInfo.tSystemInfo.ulSerialNumber);
        printf("  DPM Size:        %lu bytes\r\n", tBoardInfo.ulDpmTotalSize);
        printf("  Channel Count:   %lu\r\n", tBoardInfo.ulChannelCnt);
        printf("  HW Revision:     %u\r\n", tBoardInfo.tSystemInfo.bHwRevision);
        printf("  Device Class:    0x%04X\r\n", tBoardInfo.tSystemInfo.usDeviceClass);
    }
    else
    {
        printf("\r\n[Board Information] ERROR: 0x%08X\r\n", (unsigned int)lRet);
    }

    /* 3. 채널 정보 */
    CHANNEL_INFORMATION tChannelInfo;
    lRet = xChannelInfo(hChannel, sizeof(CHANNEL_INFORMATION), &tChannelInfo);
    if(lRet == CIFX_NO_ERROR)
    {
        printf("\r\n[Channel Information]\r\n");
        printf("  Board Name:      %s\r\n", tChannelInfo.abBoardName);
        printf("  Device Number:   %lu\r\n", tChannelInfo.ulDeviceNumber);
        printf("  Serial Number:   %lu\r\n", tChannelInfo.ulSerialNumber);

        printf("\r\n[Firmware Information]\r\n");
        printf("  Firmware Name:   %.*s\r\n",
               tChannelInfo.bFWNameLength,
               tChannelInfo.abFWName);
        printf("  FW Version:      %u.%u.%u.%u\r\n",
               tChannelInfo.usFWMajor,
               tChannelInfo.usFWMinor,
               tChannelInfo.usFWBuild,
               tChannelInfo.usFWRevision);
        printf("  FW Build Date:   %04u-%02u-%02u\r\n",
               tChannelInfo.usFWYear,
               tChannelInfo.bFWMonth,
               tChannelInfo.bFWDay);

        printf("\r\n[Channel Status]\r\n");
        printf("  Open Count:      %lu\r\n", tChannelInfo.ulOpenCnt);
        printf("  Mailbox Size:    %lu bytes\r\n", tChannelInfo.ulMailboxSize);
        printf("  IO Input Areas:  %lu\r\n", tChannelInfo.ulIOInAreaCnt);
        printf("  IO Output Areas: %lu\r\n", tChannelInfo.ulIOOutAreaCnt);
        printf("  netX Flags:      0x%08lX\r\n", tChannelInfo.ulNetxFlags);
        printf("  Host Flags:      0x%08lX\r\n", tChannelInfo.ulHostFlags);
        printf("  Device COS:      0x%08lX\r\n", tChannelInfo.ulDeviceCOSFlags);
    }
    else
    {
        printf("\r\n[Channel Information] ERROR: 0x%08X\r\n", (unsigned int)lRet);
    }

    printf("========================================\r\n\r\n");

    /* 4. DeviceNet Master Identity Information */
    printf("========================================\r\n");
    printf(" DeviceNet Master Identity\r\n");
    printf("========================================\r\n");

    DEVICENET_MASTER_IDENTITY_T tMasterIdentity;
    uint8_t masterNodeId = 0;  /* Try common master address first */

    /* Try to scan for master on network */
    lRet = DeviceNet_ScanForMaster(hChannel, &masterNodeId);

    if(lRet == CIFX_NO_ERROR)
    {
        /* Print detailed master information */
        DeviceNet_PrintMasterIdentity(&tMasterIdentity);
    }
    else
    {
        /* Scanning failed, try direct query at node 0 */
        printf("Scanning failed, trying direct query at Node 0...\r\n");
        lRet = DeviceNet_GetMasterIdentity(hChannel, 0, &tMasterIdentity);

        if(lRet == CIFX_NO_ERROR && tMasterIdentity.bDataValid)
        {
            DeviceNet_PrintMasterIdentity(&tMasterIdentity);
        }
        else
        {
            printf("ERROR: Could not retrieve Master identity\r\n");
            printf("Please verify:\r\n");
            printf("  1. DeviceNet Master is powered on\r\n");
            printf("  2. Network cables are connected\r\n");
            printf("  3. Network termination is correct\r\n");
            printf("  4. Master node address configuration\r\n");
        }
    }

    printf("========================================\r\n\r\n");
}

/**
 * @brief VAT 테스트 초기화
 *
 * VAT Adaptive Pressure Controller 테스트를 위한 초기 설정
 */
static void VAT_InitializeTest(void)
{
    printf("\r\n========================================\r\n");
    printf(" VAT DeviceNet Test Initialization\r\n");
    printf("========================================\r\n");

    /* VAT Diagnostic 초기화 */
    VAT_Diagnostic_Init();

    /* 테스트 컨텍스트 초기화 */
    VAT_Test_Init(&g_tVatContext);

    /* 테스트 설정 */
    VAT_TEST_CONFIG_T tConfig = {
        .node_address = 10,                             /* DeviceNet 노드 주소 */
        .baud_rate = 125000,                            /* 250 kbps */
        .epr_ms = 100,                                  /* 100ms 패킷 주기 */
        .input_assembly = VAT_INPUT_ASSEMBLY_100,       /* 7바이트 전체 상태 */
        .output_assembly = VAT_OUTPUT_ASSEMBLY_8,       /* 5바이트 제어+모드 */
        .enable_logging = true,                         /* 로깅 활성화 */
        .enable_validation = true                       /* 검증 활성화 */
    };

    VAT_Test_Configure(&g_tVatContext, &tConfig);

    printf("VAT Test Configuration:\r\n");
    printf("  Mode: %u (1=Basic, 2=Calibration, 3=Monitoring)\r\n", g_VatTestMode);
    printf("  Node Address: %u\r\n", tConfig.node_address);
    printf("  Baud Rate: %lu bps\r\n", tConfig.baud_rate);
    printf("  Input Assembly: 0x%02X (%u bytes)\r\n",
           tConfig.input_assembly,
           sizeof(VAT_INPUT_ASSEMBLY_100_T));
    printf("  Output Assembly: 0x%02X (%u bytes)\r\n",
           tConfig.output_assembly,
           sizeof(VAT_OUTPUT_ASSEMBLY_8_T));
    printf("========================================\r\n\r\n");
}

/**
 * @brief VAT 테스트 실행
 *
 * @param hChannel  cifX 채널 핸들
 *
 * g_VatTestMode 값에 따라 다른 테스트 시나리오 실행:
 * - 1: Basic Pressure Control (10 cycles)
 * - 2: Full Calibration (5 cycles with auto-learn)
 * - 3: Continuous Monitoring (100 cycles)
 */
static void VAT_RunTest(CIFXHANDLE hChannel)
{
    printf("\r\n========================================\r\n");
    printf(" Running VAT Test Mode: %u\r\n", g_VatTestMode);
    printf("========================================\r\n\r\n");

    switch(g_VatTestMode)
    {
        case 1:  /* Basic Pressure Control Test */
        {
            printf("Test: Basic Pressure Control\r\n");
            printf("Cycles: 10\r\n");
            printf("Setpoint: 500\r\n\r\n");

            VAT_Test_BasicPressureControl(&g_tVatContext, hChannel);
            break;
        }

        case 2:  /* Full Calibration Test */
        {
            printf("Test: Full Calibration with Auto-Learn\r\n");
            printf("Cycles: 5\r\n\r\n");

            VAT_Test_FullCalibration(&g_tVatContext, hChannel);
            break;
        }

        case 3:  /* Continuous Monitoring */
        {
            // printf("Test: Continuous Monitoring\r\n");
            // printf("Cycles: 100 (10 seconds @ 100ms)\r\n");
            // printf("Setpoint: 750\r\n\r\n");

            printf("Test: INFINITE Continuous Monitoring\r\n");
            printf("Cycles: INFINITE (until reset)\r\n");
            printf("Update Rate: 100ms\r\n");
            printf("Press RESET button to stop.\r\n\r\n");

            /* 압력 제어 모드 설정 */
            VAT_Test_SetControlMode(&g_tVatContext, VAT_CONTROL_MODE_PRESSURE);
            // VAT_Test_SetPressureSetpoint(&g_tVatContext, 750);

           /* 초기 Setpoint */
            int16_t setpoint = 500;
            VAT_Test_SetPressureSetpoint(&g_tVatContext, setpoint);

            /* 무한 연속 모니터링 루프 */
            uint32_t cycle_count = 0;

while(1)
{
    /* Setpoint 증가 */
    setpoint++;
    if(setpoint > 1000) setpoint = 0;

    /* ✅ g_tAppData에 직접 데이터 설정 (5 bytes, Master → Slave) */
    g_tAppData.tInputData.input[0] = 2;  // Control Mode = Pressure
    g_tAppData.tInputData.input[1] = (uint8_t)(setpoint & 0xFF);
    g_tAppData.tInputData.input[2] = (uint8_t)((setpoint >> 8) & 0xFF);
    g_tAppData.tInputData.input[3] = 0;  // Control Instance
    g_tAppData.tInputData.input[4] = 0;  // Reserved

    /* ✅ 출력 데이터 증가 (7 bytes, Slave → Master) */
    for(int i = 0; i < 7; i++) {
        g_tAppData.tOutputData.output[i]++;
    }

    /* ✅ 실제 DPM에 쓰기 */
    int32_t lRet = xChannelIOWrite(hChannel, 0, 0,
                                    sizeof(g_tAppData.tOutputData),
                                    &g_tAppData.tOutputData, 0);
    if(lRet != CIFX_NO_ERROR)
    {
        printf("[%lu] Write Error: 0x%08X\r\n", cycle_count, (unsigned int)lRet);
    }

    /* ✅ 실제 DPM에서 읽기 */
    lRet = xChannelIORead(hChannel, 0, 0,
                          sizeof(g_tAppData.tInputData),
                          &g_tAppData.tInputData, 0);
    if(lRet != CIFX_NO_ERROR)
    {
        printf("[%lu] Read Error: 0x%08X\r\n", cycle_count, (unsigned int)lRet);
    }

    /* ✅ VAT 진단 업데이트 (100ms마다) */
    VAT_Diagnostic_Update();

    /* ✅ Parameters ↔ I/O Data 동기화 */
    VAT_Sync_IoDataToParameters();  /* I/O → Parameters */
    VAT_Sync_ParametersToIoData();  /* Parameters → I/O */

    /* 매 10회마다 상태 출력 */
    if((cycle_count % 10) == 0)
    {
        printf("[%lu] Setpoint=%d, Output=[%02X %02X %02X %02X %02X %02X %02X]\r\n",
               cycle_count,
               setpoint,
               g_tAppData.tOutputData.output[0],
               g_tAppData.tOutputData.output[1],
               g_tAppData.tOutputData.output[2],
               g_tAppData.tOutputData.output[3],
               g_tAppData.tOutputData.output[4],
               g_tAppData.tOutputData.output[5],
               g_tAppData.tOutputData.output[6]);
    }

    HAL_Delay(100);
    cycle_count++;
}

            // while(1)
            // {
            //     /* Setpoint 증가 */
            //     setpoint++;
            //     if(setpoint > 1000) setpoint = 0;
            //     VAT_Test_SetPressureSetpoint(&g_tVatContext, setpoint);

            //     /* 제어 데이터 전송 */
            //     int32_t lRet = VAT_Test_WriteOutput(&g_tVatContext, hChannel);
            //     if(lRet != CIFX_NO_ERROR)
            //     {
            //         printf("[%lu] Write Error: 0x%08X\r\n", cycle_count, (unsigned int)lRet);
            //     }

            //     /* 센서 데이터 읽기 */
            //     lRet = VAT_Test_ReadInput(&g_tVatContext, hChannel);
            //     if(lRet != CIFX_NO_ERROR)
            //     {
            //         printf("[%lu] Read Error: 0x%08X\r\n", cycle_count, (unsigned int)lRet);
            //     }

            //     /* 예외 상태 확인 */
            //     if(VAT_Test_HasException(&g_tVatContext))
            //     {
            //         printf("[%lu] WARNING: Exception 0x%02X\r\n",
            //                cycle_count, VAT_Test_GetExceptionStatus(&g_tVatContext));
            //     }

            //     /* 매 10회마다 상태 출력 */
            //     if((cycle_count % 10) == 0 && g_tVatContext.input_data_valid)
            //     {
            //         printf("[%lu] Setpoint=%d, Pressure=%d, Position=%d, Status=0x%02X\r\n",
            //                cycle_count,
            //                setpoint,
            //                g_tVatContext.input_asm100.pressure,
            //                g_tVatContext.input_asm100.position,
            //                g_tVatContext.input_asm100.device_status);
            //     }

            //     /* 100ms 대기 */
            //     HAL_Delay(100);

            //     cycle_count++;

            //     /* 1000회마다 진행 상황 출력 */
            //     if((cycle_count % 1000) == 0)
            //     {
            //         printf("\r\n*** Running for %lu cycles (%.1f minutes) ***\r\n",
            //                cycle_count, (float)cycle_count / 600.0f);
            //     }
            // }

     /*

            for(int i = 0; i < 100; i++)
            {

                int32_t lRet = VAT_Test_WriteOutput(&g_tVatContext, hChannel);
                if(lRet != CIFX_NO_ERROR)
                {
                    printf("[%03d] Write Error: 0x%08X\r\n", i, (unsigned int)lRet);
                }

                lRet = VAT_Test_ReadInput(&g_tVatContext, hChannel);
                if(lRet != CIFX_NO_ERROR)
                {
                    printf("[%03d] Read Error: 0x%08X\r\n", i, (unsigned int)lRet);
                }

                 예외 상태 확인
                if(VAT_Test_HasException(&g_tVatContext))
                {
                    printf("[%03d] WARNING: Exception 0x%02X\r\n",
                           i, VAT_Test_GetExceptionStatus(&g_tVatContext));
                }

                // 매 10회마다 상태 출력
                if((i % 10) == 0 && g_tVatContext.input_data_valid)
                {
                    printf("[%03d] Pressure=%d, Position=%d, Status=0x%02X\r\n",
                           i,
                           g_tVatContext.input_asm100.pressure,
                           g_tVatContext.input_asm100.position,
                           g_tVatContext.input_asm100.device_status);
                }

                // 100ms 대기
                HAL_Delay(100);
            }

            printf("\r\nContinuous monitoring completed.\r\n");
            break;
        } */
          }

case 4:  /* VAT Real Data Simulation - INFINITE */
{
    printf("Test: VAT Real Data Simulation (INFINITE)\r\n");
    printf("Simulating VAT Adaptive Pressure Controller\r\n");
    printf("Press RESET to stop.\r\n\r\n");

    /* 시뮬레이션 상태 초기화 */
    memset(&g_tVatSimState, 0, sizeof(g_tVatSimState));
    g_tVatSimState.current_pressure = 0;
    g_tVatSimState.current_position = 0;
    g_tVatSimState.device_status = 0x02;  // VALVE_CLOSED
    g_tVatSimState.exception_status = 0x00;

    uint32_t cycle_count = 0;

    /* 무한 제어 루프 */
    while(1)
    {
        /* === Master → Slave: 제어 명령 읽기 === */
        int32_t lRet = xChannelIORead(hChannel, 0, 0,
                                       sizeof(g_tAppData.tInputData),
                                       &g_tAppData.tInputData, 0);
        if(lRet != CIFX_NO_ERROR) {
            printf("[%lu] Read Error: 0x%08X\r\n", cycle_count, (unsigned int)lRet);
        }

        /* Master로부터 받은 제어 명령 파싱 */
        uint8_t control_mode = g_tAppData.tInputData.input[0];
        int16_t control_setpoint = (int16_t)(g_tAppData.tInputData.input[1] |
                                             (g_tAppData.tInputData.input[2] << 8));

        /* === 제어 모드에 따른 시뮬레이션 === */
        switch(control_mode)
        {
            case 0x00:  /* CLOSED */
                if(g_tVatSimState.current_position > 0) {
                    g_tVatSimState.current_position -= 10;
                    if(g_tVatSimState.current_position < 0)
                        g_tVatSimState.current_position = 0;
                    g_tVatSimState.device_status |= 0x04;  // MOVING
                } else {
                    g_tVatSimState.device_status &= ~0x04;
                    g_tVatSimState.device_status |= 0x02;  // VALVE_CLOSED
                }
                g_tVatSimState.current_pressure = 869;
                break;

            case 0x01:  /* OPEN */
                if(g_tVatSimState.current_position < 1000) {
                    g_tVatSimState.current_position += 10;
                    if(g_tVatSimState.current_position > 1000)
                        g_tVatSimState.current_position = 1000;
                    g_tVatSimState.device_status |= 0x04;  // MOVING
                } else {
                    g_tVatSimState.device_status &= ~0x04;
                    g_tVatSimState.device_status |= 0x01;  // VALVE_OPEN
                }
                g_tVatSimState.current_pressure = 10;
                break;

            case 0x02:  /* PRESSURE */
            {
                int16_t pressure_error = control_setpoint - g_tVatSimState.current_pressure;

                if(abs(pressure_error) <= 10) {
                    /* 설정값 도달 */
                    g_tVatSimState.device_status |= 0x08;   // AT_SETPOINT
                    g_tVatSimState.device_status &= ~0x04;  // MOVING 해제
                } else {
                    /* 압력 조정 중 */
                    g_tVatSimState.device_status |= 0x04;   // MOVING
                    g_tVatSimState.device_status &= ~0x08;  // AT_SETPOINT 해제

                    /* 밸브 위치 조정 */
                    if(pressure_error > 0) {
                        g_tVatSimState.current_position += 5;
                        if(g_tVatSimState.current_position > 1000)
                            g_tVatSimState.current_position = 1000;
                    } else {
                        g_tVatSimState.current_position -= 5;
                        if(g_tVatSimState.current_position < 0)
                            g_tVatSimState.current_position = 0;
                    }

                    /* 압력 업데이트 (간단한 모델) */
                    g_tVatSimState.current_pressure =
                        (g_tVatSimState.current_position * control_setpoint) / 1000;
                }
                break;
            }

            case 0x03:  /* POSITION */
            {
                int16_t position_error = control_setpoint - g_tVatSimState.current_position;

                if(abs(position_error) <= 5) {
                    g_tVatSimState.device_status |= 0x08;
                    g_tVatSimState.device_status &= ~0x04;
                } else {
                    g_tVatSimState.device_status |= 0x04;
                    g_tVatSimState.device_status &= ~0x08;

                    if(position_error > 0) {
                        g_tVatSimState.current_position += 10;
                        if(g_tVatSimState.current_position > 1000)
                            g_tVatSimState.current_position = 1000;
                    } else {
                        g_tVatSimState.current_position -= 10;
                        if(g_tVatSimState.current_position < 0)
                            g_tVatSimState.current_position = 0;
                    }
                }

                /* 위치에 따른 압력 (최대 1000 mbar) */
                // g_tVatSimState.current_pressure = g_tVatSimState.current_position;
                break;
            }

            default:
                /* 알 수 없는 모드 - 안전을 위해 닫힘 */
                g_tVatSimState.current_position = 0;
                g_tVatSimState.current_pressure = 0;
                g_tVatSimState.device_status = 0x02;  // VALVE_CLOSED
                break;
        }

        /* 밸브 완전 열림/닫힘 플래그 갱신 */
        if(g_tVatSimState.current_position >= 1000) {
            g_tVatSimState.device_status |= 0x01;   // VALVE_OPEN
            g_tVatSimState.device_status &= ~0x02;
        } else if(g_tVatSimState.current_position <= 0) {
            g_tVatSimState.device_status |= 0x02;   // VALVE_CLOSED
            g_tVatSimState.device_status &= ~0x01;
        } else {
            g_tVatSimState.device_status &= ~0x03;  // 중간 상태
        }

        /* === Slave → Master: 센서 데이터 전송 === */
        g_tAppData.tOutputData.output[0] = g_tVatSimState.exception_status;
        g_tAppData.tOutputData.output[1] = (uint8_t)(g_tVatSimState.current_pressure & 0xFF);
        g_tAppData.tOutputData.output[2] = (uint8_t)((g_tVatSimState.current_pressure >> 8) & 0xFF);
        g_tAppData.tOutputData.output[3] = (uint8_t)(g_tVatSimState.current_position & 0xFF);
        g_tAppData.tOutputData.output[4] = (uint8_t)((g_tVatSimState.current_position >> 8) & 0xFF);
        g_tAppData.tOutputData.output[5] = g_tVatSimState.device_status;
        g_tAppData.tOutputData.output[6] = 0x00;  // access_mode (reserved)

        /* DPM에 쓰기 */
        lRet = xChannelIOWrite(hChannel, 0, 0,
                               sizeof(g_tAppData.tOutputData),
                               &g_tAppData.tOutputData, 0);
        if(lRet != CIFX_NO_ERROR) {
            printf("[%lu] Write Error: 0x%08X\r\n", cycle_count, (unsigned int)lRet);
        }

        /* 매 10회마다 상태 출력 */
        if((cycle_count % 10) == 0) {
            printf("[%lu] Mode=%d, Setpoint=%d, Pressure=%d, Position=%d, Status=0x%02X\r\n",
                   cycle_count,
                   control_mode,
                   control_setpoint,
                   g_tVatSimState.current_pressure,
                   g_tVatSimState.current_position,
                   g_tVatSimState.device_status);
        }

        /* 100ms 대기 */
        HAL_Delay(100);
        cycle_count++;

        /* 1000회마다 진행 상황 */
        if((cycle_count % 1000) == 0) {
            printf("\r\n*** VAT Simulation running for %lu cycles (%.1f min) ***\r\n",
                   cycle_count, (float)cycle_count / 600.0f);
        }
    }

    break;
}

        default:
        {
            printf("ERROR: Invalid test mode %u\r\n", g_VatTestMode);
            printf("Valid modes: 1 (Basic), 2 (Calibration), 3 (Monitoring)\r\n");
            break;
        }
    }

    printf("\r\n========================================\r\n");
    printf(" VAT Test Completed\r\n");
    printf("========================================\r\n");

    /* 최종 통계 출력 */
    VAT_Test_PrintStats(&g_tVatContext);
}

/* ========== VAT TEST INTEGRATION - 함수 구현 끝 ========== */

/* USER CODE END 0 */

int main(void)
{

  /* USER CODE BEGIN 1 */
	 int32_t lRet=CIFX_NO_ERROR;    /* Return value for common error codes      */
  /* USER CODE END 1 */

  /* MCU Configuration--------------------------------------------------------*/

  /* Reset of all peripherals, Initializes the Flash interface and the Systick. */
  HAL_Init();

  /* Configure the system clock */
  SystemClock_Config();

  /* Initialize all configured peripherals */
  MX_GPIO_Init();
  MX_TIM1_Init();
  MX_USART1_UART_Init();
  MX_USB_HOST_Init();
  MX_TIM3_Init();
  MX_SPI4_Init();
  MX_UART5_Init();
  /* USER CODE BEGIN 2 */

  UART_Ring_Init(&huart5);  // 인터럽트 수신 초기화

//  for (int i = 0; i<10; i++){
//	  HAL_UART_Transmit(&huart1, (uint8_t *)"RX: ", 4, HAL_MAX_DELAY);
//	  HAL_Delay(1000);
//
//  }

//  HAL_UART_Transmit(&huart1, (uint8_t *)"RX: ", 4, HAL_MAX_DELAY);
//            HAL_UART_Transmit(&huart1, line, len, HAL_MAX_DELAY);
//            HAL_UART_Transmit(&huart1, (uint8_t *)"\r\n", 2, HAL_MAX_DELAY);

  /* UART printf 테스트 */
  printf("\r\n\r\n");
  printf("========================================\r\n");
  printf(" STM32F429 + netX90 System Starting\r\n");
  printf("========================================\r\n");
  printf("UART5: 115200 baud, 8N1\r\n");
  printf("Date: 2025-10-28\r\n");
  printf("========================================\r\n\r\n");

  // D switch validation loop - simple single reception
  // HAL_UART_Transmit(&huart5, (uint8_t *)"Starting D validation loop (waiting for D:[xxxx] + 0x0D)...\r\n", 62, HAL_MAX_DELAY);

  /*
  // 수정된 부분: 복잡한 누적 로직을 제거하고, 라인 단위로 수신
  while (!g_bDipDataValid)
  {
      int len = UART_Ring_ReadLine(line, sizeof(line));

      if (len > 0)
      {
          // A full line was received. Echo it back.
          HAL_UART_Transmit(&huart5, (uint8_t *)"RX: ", 4, HAL_MAX_DELAY);
          HAL_UART_Transmit(&huart5, line, len, HAL_MAX_DELAY);
          HAL_UART_Transmit(&huart5, (uint8_t *)"\r\n", 2, HAL_MAX_DELAY);

          // Now validate the received line
          if (ValidateDipSwitchData(line) == 1)
          {
              HAL_UART_Transmit(&huart5, (uint8_t *)"D data validated!\r\n", 19, HAL_MAX_DELAY);
              break; // Exit validation loop
          }
          else
          {
              // Validation failed, continue waiting for a new line
              HAL_UART_Transmit(&huart5, (uint8_t *)"Validation FAILED, waiting for new data.\r\n", 42, HAL_MAX_DELAY);
          }
      }

      HAL_Delay(100); // Short delay to prevent busy-waiting
  }
  */

  lRet = InitializeToolkit();

  if(CIFX_NO_ERROR == lRet)
  {
      /* ========== VAT TEST INTEGRATION - 메인 로직 수정 시작 ========== */

      if(g_bEnableVatTest)
      {
          /* VAT 테스트 모드 */
          CIFXHANDLE hDriver = NULL;
          CIFXHANDLE hChannel = NULL;

          /* VAT 테스트 초기화 */
          VAT_InitializeTest();

          /* cifX 드라이버 열기 */
          lRet = xDriverOpen(&hDriver);
          if(CIFX_NO_ERROR == lRet)
          {
              /* 채널 0 열기 */
              lRet = xChannelOpen(hDriver, "cifX0", 0, &hChannel);
              if(CIFX_NO_ERROR == lRet)
              {
                  /* ========== DeviceNet 스택 초기화 시작 ========== */
                  printf("\r\n");
                  printf("========================================\r\n");
                  printf(" DeviceNet Stack Initialization\r\n");
                  printf("========================================\r\n");

                  /* g_tAppData 채널 0 설정 */
                  if(g_tAppData.aptChannels[0] == NULL)
                  {
                      g_tAppData.aptChannels[0] = (APP_COMM_CHANNEL_T*)calloc(1, sizeof(APP_COMM_CHANNEL_T));
                      if(g_tAppData.aptChannels[0] == NULL)
                      {
                          printf("ERROR: Failed to allocate memory for channel 0\r\n");
                          lRet = CIFX_DRV_INIT_ERROR;
                      }
                  }

                  if(lRet == CIFX_NO_ERROR)
                  {
                      /* 채널 핸들 및 프로토콜 핸들러 설정 */
                      g_tAppData.aptChannels[0]->hChannel = hChannel;
                      g_tAppData.aptChannels[0]->tProtocol = g_tRealtimeProtocolHandlers;

                      /* ========== CRITICAL: Wait for channel ready BEFORE configuration! ========== */
                      printf("\r\nStep 1: Waiting for channel to be ready...\r\n");
                      CHANNEL_INFORMATION tChannelInfo;
                      uint32_t timeout_ms = 0;
                      const uint32_t MAX_WAIT_MS = 5000;

                      do {
                          xChannelInfo(hChannel, sizeof(CHANNEL_INFORMATION), &tChannelInfo);

                          if(tChannelInfo.ulDeviceCOSFlags & HIL_COMM_COS_READY)
                              break;

                          HAL_Delay(100);
                          timeout_ms += 100;

                          if((timeout_ms % 1000) == 0) {
                              printf("  [%lu s] COS Flags: 0x%08X\r\n",
                                     timeout_ms / 1000,
                                     (unsigned int)tChannelInfo.ulDeviceCOSFlags);
                          }

                          if(timeout_ms >= MAX_WAIT_MS) {
                              printf("ERROR: Channel ready timeout!\r\n");
                              lRet = CIFX_DEV_NOT_READY;
                              break;
                          }
                      } while(1);

                      if(lRet == CIFX_NO_ERROR) {
                          printf("  Channel ready! COS Flags: 0x%08X\r\n",
                                 (unsigned int)tChannelInfo.ulDeviceCOSFlags);

                          /* Set Host State to READY */
                          printf("\r\nStep 2: Setting Host State to READY...\r\n");
                          uint32_t ulState = 0;
                          lRet = xChannelHostState(hChannel, CIFX_HOST_STATE_READY, &ulState, 1000);
                          if(lRet == CIFX_NO_ERROR) {
                              printf("  Host State set to READY (State: 0x%08X)\r\n", (unsigned int)ulState);
                          } else {
                              printf("ERROR: xChannelHostState failed: 0x%08X\r\n", (unsigned int)lRet);
                          }
                      }

                      if(lRet == CIFX_NO_ERROR)
                      {
                          printf("\r\nStep 3: Calling Protocol_StartConfiguration...\r\n");

                          /* Protocol Start Configuration (includes Pkt_Init and RegisterIndicationHandler) */
                          if(g_tAppData.aptChannels[0]->tProtocol.pfStartChannelConfiguration != NULL)
                          {
                              lRet = g_tAppData.aptChannels[0]->tProtocol.pfStartChannelConfiguration(&g_tAppData);
                              if(lRet != CIFX_NO_ERROR)
                              {
                                  printf("ERROR: Protocol_StartConfiguration failed: 0x%08X\r\n", (unsigned int)lRet);
                              }
                          }
                          else
                          {
                              printf("ERROR: pfStartChannelConfiguration is NULL!\r\n");
                              lRet = CIFX_DRV_INIT_ERROR;
                          }
                      }

                      if(lRet == CIFX_NO_ERROR)
                      {
                          printf("  [OK] Protocol_StartConfiguration completed\r\n");
                          printf("    - Pkt_Init() done\r\n");
                          printf("    - Pkt_RegisterIndicationHandler() done\r\n");
                          printf("    - Application registered (if DNS_HOST_APP_REGISTRATION defined)\r\n");
                          printf("    - Stack configuration (SetConfig, ChannelInit, StartComm) done\r\n");

                          /* Initialize VAT Parameter Manager */
                          printf("\r\nStep 4: Initializing VAT Parameters...\r\n");
                          VAT_Param_Init(&g_tParamManager);
                          printf("  VAT Parameter Manager initialized (%d parameters)\r\n",
                                 g_tParamManager.param_count);

                          printf("\r\n========================================\r\n");
                          printf("DeviceNet Stack initialized successfully!\r\n");
                          printf("Waiting for Explicit Messages from master...\r\n");
                          printf("\r\nNOTE: CIP Service Indications will be logged below\r\n");
                          printf("========================================\r\n\r\n");

                          /* ⭐ Print stack status for debugging Explicit messaging */
                          PrintDeviceNetStatus(&g_tAppData);
                      }
                      else
                      {
                          printf("Step 1: ❌ AppDNS_ConfigureStack() FAILED\r\n");
                          printf("  Error Code: 0x%08X\r\n", (unsigned int)lRet);
                          printf("\r\nDeviceNet Stack initialization failed!\r\n");
                          printf("Master scan will NOT detect this slave.\r\n");
                          printf("========================================\r\n\r\n");
                      }
                  }
                  /* ========== DeviceNet 스택 초기화 끝 ========== */

                  /* Continue with testing if initialization succeeded */
                  if(lRet == CIFX_NO_ERROR)
                  {
                      /* 디바이스 정보 출력 */
                      PrintDeviceInformation(hDriver, hChannel);

                      /* ========== Main Communication Loop ========== */
                      printf("\r\n========================================\r\n");
                      printf(" Entering Main Communication Loop\r\n");
                      printf(" - Processing Explicit Messages\r\n");
                      printf(" - Handling IO Data\r\n");
                      printf(" Press RESET to stop\r\n");
                      printf("========================================\r\n\r\n");

                      uint32_t loop_count = 0;
                      while(1)
                      {
                          /* Process incoming packets (Explicit Messages) - CRITICAL! */
                          lRet = App_AllChannels_PacketHandler(&g_tAppData);
                          if(lRet != CIFX_NO_ERROR)
                          {
                              printf("ERROR: PacketHandler failed: 0x%08X\r\n", (unsigned int)lRet);
                          }

                          /* TODO: Process IO Data here if needed */
                          /* For now, just focus on Explicit Messages */

                          /* Periodic status output every 10 seconds */
                          if((loop_count % 1000) == 0)
                          {
                              printf("[%lu] Communication active, waiting for Explicit Messages...\r\n",
                                     loop_count / 100);
                          }

                          HAL_Delay(10);  /* 10ms cycle time */
                          loop_count++;
                      }
                  }
                  else
                  {
                      printf("\r\n*** Skipping communication loop due to initialization failure ***\r\n");
                  }

                  /* ✅ 수정: 채널은 닫지 않고 유지 - 계속 통신 가능하도록 */
                  printf("\r\n*** VAT Test completed - keeping channel open for continuous operation ***\r\n");
                  // xChannelClose(hChannel);  /* 주석 처리: 통신 유지 */
              }
              else
              {
                  printf("ERROR: xChannelOpen failed: 0x%08X\r\n", (unsigned int)lRet);
              }

              /* ✅ 수정: 드라이버도 닫지 않고 유지 - 계속 통신 가능하도록 */
              // xDriverClose(hDriver);  /* 주석 처리: 통신 유지 */
          }
          else
          {
              printf("ERROR: xDriverOpen failed: 0x%08X\r\n", (unsigned int)lRet);
          }

          /* ✅ 수정: 통계 출력만 수행하고 채널은 유지 */
          printf("\r\n========================================\r\n");
          printf(" VAT Test Statistics\r\n");
          printf("========================================\r\n");
          VAT_Test_PrintStats(&g_tVatContext);
          printf("Communication channel remains active.\r\n");
          printf("========================================\r\n\r\n");
          // VAT_Test_Deinit(&g_tVatContext);  /* 주석 처리: 통신 유지 */
      }
      else
      {
          /* 기존 App_CifXApplicationDemo 실행 */
          printf("Running original App_CifXApplicationDemo...\r\n");
          lRet = App_CifXApplicationDemo("cifX0");
      }

      /* ========== VAT TEST INTEGRATION - 메인 로직 수정 끝 ========== */
  }
  /* USER CODE END 2 */

  /* Infinite loop */
  while (1)
  {
    MX_USB_HOST_Process();

  }
}

void SystemClock_Config(void)
{
  RCC_OscInitTypeDef RCC_OscInitStruct = {0};
  RCC_ClkInitTypeDef RCC_ClkInitStruct = {0};

  /** Configure the main internal regulator output voltage
  */
  __HAL_RCC_PWR_CLK_ENABLE();
  __HAL_PWR_VOLTAGESCALING_CONFIG(PWR_REGULATOR_VOLTAGE_SCALE3);

  /** Initializes the RCC Oscillators according to the specified parameters
  * in the RCC_OscInitTypeDef structure.
  */
  RCC_OscInitStruct.OscillatorType = RCC_OSCILLATORTYPE_HSE;
  RCC_OscInitStruct.HSEState = RCC_HSE_ON;
  RCC_OscInitStruct.PLL.PLLState = RCC_PLL_ON;
  RCC_OscInitStruct.PLL.PLLSource = RCC_PLLSOURCE_HSE;
  RCC_OscInitStruct.PLL.PLLM = 4;
  RCC_OscInitStruct.PLL.PLLN = 72;
  RCC_OscInitStruct.PLL.PLLP = RCC_PLLP_DIV2;
  RCC_OscInitStruct.PLL.PLLQ = 3;
  if (HAL_RCC_OscConfig(&RCC_OscInitStruct) != HAL_OK)
  {
    Error_Handler();
  }

  /** Initializes the CPU, AHB and APB buses clocks
  */
  RCC_ClkInitStruct.ClockType = RCC_CLOCKTYPE_HCLK|RCC_CLOCKTYPE_SYSCLK
                              |RCC_CLOCKTYPE_PCLK1|RCC_CLOCKTYPE_PCLK2;
  RCC_ClkInitStruct.SYSCLKSource = RCC_SYSCLKSOURCE_PLLCLK;
  RCC_ClkInitStruct.AHBCLKDivider = RCC_SYSCLK_DIV1;
  RCC_ClkInitStruct.APB1CLKDivider = RCC_HCLK_DIV2;
  RCC_ClkInitStruct.APB2CLKDivider = RCC_HCLK_DIV1;

  if (HAL_RCC_ClockConfig(&RCC_ClkInitStruct, FLASH_LATENCY_2) != HAL_OK)
  {
    Error_Handler();
  }
}

static void MX_SPI4_Init(void)
{

  /* SPI4 parameter configuration*/
  hspi4.Instance = SPI4;
  hspi4.Init.Mode = SPI_MODE_MASTER;
  hspi4.Init.Direction = SPI_DIRECTION_2LINES;
  hspi4.Init.DataSize = SPI_DATASIZE_8BIT;
  hspi4.Init.CLKPolarity = SPI_POLARITY_HIGH;
  hspi4.Init.CLKPhase = SPI_PHASE_2EDGE;
  hspi4.Init.NSS = SPI_NSS_SOFT;
  hspi4.Init.BaudRatePrescaler = SPI_BAUDRATEPRESCALER_8;
  hspi4.Init.FirstBit = SPI_FIRSTBIT_MSB;
  hspi4.Init.TIMode = SPI_TIMODE_DISABLE;
  hspi4.Init.CRCCalculation = SPI_CRCCALCULATION_DISABLE;
  hspi4.Init.CRCPolynomial = 10;
  if (HAL_SPI_Init(&hspi4) != HAL_OK)
  {
    Error_Handler();
  }

}

static void MX_TIM1_Init(void)
{

  TIM_ClockConfigTypeDef sClockSourceConfig = {0};
  TIM_MasterConfigTypeDef sMasterConfig = {0};

  htim1.Instance = TIM1;
  htim1.Init.Prescaler = 0;
  htim1.Init.CounterMode = TIM_COUNTERMODE_UP;
  htim1.Init.Period = 65535;
  htim1.Init.ClockDivision = TIM_CLOCKDIVISION_DIV1;
  htim1.Init.RepetitionCounter = 0;
  htim1.Init.AutoReloadPreload = TIM_AUTORELOAD_PRELOAD_DISABLE;
  if (HAL_TIM_Base_Init(&htim1) != HAL_OK)
  {
    Error_Handler();
  }
  sClockSourceConfig.ClockSource = TIM_CLOCKSOURCE_INTERNAL;
  if (HAL_TIM_ConfigClockSource(&htim1, &sClockSourceConfig) != HAL_OK)
  {
    Error_Handler();
  }
  sMasterConfig.MasterOutputTrigger = TIM_TRGO_RESET;
  sMasterConfig.MasterSlaveMode = TIM_MASTERSLAVEMODE_DISABLE;
  if (HAL_TIMEx_MasterConfigSynchronization(&htim1, &sMasterConfig) != HAL_OK)
  {
    Error_Handler();
  }

}

static void MX_TIM3_Init(void)
{

  TIM_ClockConfigTypeDef sClockSourceConfig = {0};
  TIM_MasterConfigTypeDef sMasterConfig = {0};

  htim3.Instance = TIM3;
  htim3.Init.Prescaler = 200-1;
  htim3.Init.CounterMode = TIM_COUNTERMODE_UP;
  htim3.Init.Period = 1000-1;
  htim3.Init.ClockDivision = TIM_CLOCKDIVISION_DIV1;
  htim3.Init.AutoReloadPreload = TIM_AUTORELOAD_PRELOAD_DISABLE;
  if (HAL_TIM_Base_Init(&htim3) != HAL_OK)
  {
    Error_Handler();
  }
  sClockSourceConfig.ClockSource = TIM_CLOCKSOURCE_INTERNAL;
  if (HAL_TIM_ConfigClockSource(&htim3, &sClockSourceConfig) != HAL_OK)
  {
    Error_Handler();
  }
  sMasterConfig.MasterOutputTrigger = TIM_TRGO_RESET;
  sMasterConfig.MasterSlaveMode = TIM_MASTERSLAVEMODE_DISABLE;
  if (HAL_TIMEx_MasterConfigSynchronization(&htim3, &sMasterConfig) != HAL_OK)
  {
    Error_Handler();
  }

}

static void MX_UART5_Init(void)
{

  huart5.Instance = UART5;
  huart5.Init.BaudRate = 115200;
  huart5.Init.WordLength = UART_WORDLENGTH_8B;
  huart5.Init.StopBits = UART_STOPBITS_1;
  huart5.Init.Parity = UART_PARITY_NONE;
  huart5.Init.Mode = UART_MODE_TX_RX;
  huart5.Init.HwFlowCtl = UART_HWCONTROL_NONE;
  huart5.Init.OverSampling = UART_OVERSAMPLING_16;
  if (HAL_UART_Init(&huart5) != HAL_OK)
  {
    Error_Handler();
  }

}

static void MX_USART1_UART_Init(void)
{

  huart1.Instance = USART1;
  huart1.Init.BaudRate = 115200;
  huart1.Init.WordLength = UART_WORDLENGTH_8B;
  huart1.Init.StopBits = UART_STOPBITS_1;
  huart1.Init.Parity = UART_PARITY_NONE;
  huart1.Init.Mode = UART_MODE_TX_RX;
  huart1.Init.HwFlowCtl = UART_HWCONTROL_NONE;
  huart1.Init.OverSampling = UART_OVERSAMPLING_16;
  if (HAL_UART_Init(&huart1) != HAL_OK)
  {
    Error_Handler();
  }

}

static void MX_GPIO_Init(void)
{
  GPIO_InitTypeDef GPIO_InitStruct = {0};

  /* GPIO Ports Clock Enable */
  __HAL_RCC_GPIOE_CLK_ENABLE();
  __HAL_RCC_GPIOC_CLK_ENABLE();
  __HAL_RCC_GPIOF_CLK_ENABLE();
  __HAL_RCC_GPIOH_CLK_ENABLE();
  __HAL_RCC_GPIOA_CLK_ENABLE();
  __HAL_RCC_GPIOB_CLK_ENABLE();
  __HAL_RCC_GPIOG_CLK_ENABLE();
  __HAL_RCC_GPIOD_CLK_ENABLE();

  /*Configure GPIO pin Output Level */
  HAL_GPIO_WritePin(GPIOC, NCS_MEMS_SPI_Pin|CSX_Pin|OTG_FS_PSO_Pin, GPIO_PIN_RESET);

  /*Configure GPIO pin Output Level */
  HAL_GPIO_WritePin(GPIOA, SPI5_CS_Pin|GPIO_PIN_6|ACP_RST_Pin, GPIO_PIN_RESET);

  /*Configure GPIO pin Output Level */
  HAL_GPIO_WritePin(GPIOD, RDX_Pin|WRX_DCX_Pin, GPIO_PIN_RESET);

  /*Configure GPIO pin Output Level */
  HAL_GPIO_WritePin(GPIOG, LD3_Pin|LD4_Pin, GPIO_PIN_RESET);

  /*Configure GPIO pins : A0_Pin A1_Pin A2_Pin A3_Pin
                           A4_Pin A5_Pin SDNRAS_Pin A6_Pin
                           A7_Pin A8_Pin A9_Pin */
  GPIO_InitStruct.Pin = A0_Pin|A1_Pin|A2_Pin|A3_Pin
                          |A4_Pin|A5_Pin|SDNRAS_Pin|A6_Pin
                          |A7_Pin|A8_Pin|A9_Pin;
  GPIO_InitStruct.Mode = GPIO_MODE_AF_PP;
  GPIO_InitStruct.Pull = GPIO_NOPULL;
  GPIO_InitStruct.Speed = GPIO_SPEED_FREQ_VERY_HIGH;
  GPIO_InitStruct.Alternate = GPIO_AF12_FMC;
  HAL_GPIO_Init(GPIOF, &GPIO_InitStruct);

  /*Configure GPIO pins : SPI5_SCK_Pin SPI5_MISO_Pin SPI5_MOSI_Pin */
  GPIO_InitStruct.Pin = SPI5_SCK_Pin|SPI5_MISO_Pin|SPI5_MOSI_Pin;
  GPIO_InitStruct.Mode = GPIO_MODE_AF_PP;
  GPIO_InitStruct.Pull = GPIO_NOPULL;
  GPIO_InitStruct.Speed = GPIO_SPEED_FREQ_LOW;
  GPIO_InitStruct.Alternate = GPIO_AF5_SPI5;
  HAL_GPIO_Init(GPIOF, &GPIO_InitStruct);

  /*Configure GPIO pin : ENABLE_Pin */
  GPIO_InitStruct.Pin = ENABLE_Pin;
  GPIO_InitStruct.Mode = GPIO_MODE_AF_PP;
  GPIO_InitStruct.Pull = GPIO_NOPULL;
  GPIO_InitStruct.Speed = GPIO_SPEED_FREQ_LOW;
  GPIO_InitStruct.Alternate = GPIO_AF14_LTDC;
  HAL_GPIO_Init(ENABLE_GPIO_Port, &GPIO_InitStruct);

  /*Configure GPIO pin : SDNWE_Pin */
  GPIO_InitStruct.Pin = SDNWE_Pin;
  GPIO_InitStruct.Mode = GPIO_MODE_AF_PP;
  GPIO_InitStruct.Pull = GPIO_NOPULL;
  GPIO_InitStruct.Speed = GPIO_SPEED_FREQ_VERY_HIGH;
  GPIO_InitStruct.Alternate = GPIO_AF12_FMC;
  HAL_GPIO_Init(SDNWE_GPIO_Port, &GPIO_InitStruct);

  /*Configure GPIO pins : NCS_MEMS_SPI_Pin CSX_Pin OTG_FS_PSO_Pin */
  GPIO_InitStruct.Pin = NCS_MEMS_SPI_Pin|CSX_Pin|OTG_FS_PSO_Pin;
  GPIO_InitStruct.Mode = GPIO_MODE_OUTPUT_PP;
  GPIO_InitStruct.Pull = GPIO_NOPULL;
  GPIO_InitStruct.Speed = GPIO_SPEED_FREQ_LOW;
  HAL_GPIO_Init(GPIOC, &GPIO_InitStruct);

  /*Configure GPIO pins : B1_Pin MEMS_INT1_Pin MEMS_INT2_Pin TP_INT1_Pin */
  GPIO_InitStruct.Pin = B1_Pin|MEMS_INT1_Pin|MEMS_INT2_Pin|TP_INT1_Pin;
  GPIO_InitStruct.Mode = GPIO_MODE_EVT_RISING;
  GPIO_InitStruct.Pull = GPIO_NOPULL;
  HAL_GPIO_Init(GPIOA, &GPIO_InitStruct);

  /*Configure GPIO pins : B5_Pin VSYNC_Pin R4_Pin R5_Pin */
  GPIO_InitStruct.Pin = B5_Pin|VSYNC_Pin|R4_Pin|R5_Pin;
  GPIO_InitStruct.Mode = GPIO_MODE_AF_PP;
  GPIO_InitStruct.Pull = GPIO_NOPULL;
  GPIO_InitStruct.Speed = GPIO_SPEED_FREQ_LOW;
  GPIO_InitStruct.Alternate = GPIO_AF14_LTDC;
  HAL_GPIO_Init(GPIOA, &GPIO_InitStruct);

  /*Configure GPIO pins : SPI5_CS_Pin PA6 ACP_RST_Pin */
  GPIO_InitStruct.Pin = SPI5_CS_Pin|GPIO_PIN_6|ACP_RST_Pin;
  GPIO_InitStruct.Mode = GPIO_MODE_OUTPUT_PP;
  GPIO_InitStruct.Pull = GPIO_NOPULL;
  GPIO_InitStruct.Speed = GPIO_SPEED_FREQ_LOW;
  HAL_GPIO_Init(GPIOA, &GPIO_InitStruct);

  /*Configure GPIO pin : OTG_FS_OC_Pin */
  GPIO_InitStruct.Pin = OTG_FS_OC_Pin;
  GPIO_InitStruct.Mode = GPIO_MODE_EVT_RISING;
  GPIO_InitStruct.Pull = GPIO_NOPULL;
  HAL_GPIO_Init(OTG_FS_OC_GPIO_Port, &GPIO_InitStruct);

  /*Configure GPIO pins : R3_Pin R6_Pin */
  GPIO_InitStruct.Pin = R3_Pin|R6_Pin;
  GPIO_InitStruct.Mode = GPIO_MODE_AF_PP;
  GPIO_InitStruct.Pull = GPIO_NOPULL;
  GPIO_InitStruct.Speed = GPIO_SPEED_FREQ_LOW;
  GPIO_InitStruct.Alternate = GPIO_AF9_LTDC;
  HAL_GPIO_Init(GPIOB, &GPIO_InitStruct);

  /*Configure GPIO pin : BOOT1_Pin */
  GPIO_InitStruct.Pin = BOOT1_Pin;
  GPIO_InitStruct.Mode = GPIO_MODE_INPUT;
  GPIO_InitStruct.Pull = GPIO_NOPULL;
  HAL_GPIO_Init(BOOT1_GPIO_Port, &GPIO_InitStruct);

  /*Configure GPIO pins : A10_Pin A11_Pin BA0_Pin BA1_Pin
                           SDCLK_Pin SDNCAS_Pin */
  GPIO_InitStruct.Pin = A10_Pin|A11_Pin|BA0_Pin|BA1_Pin
                          |SDCLK_Pin|SDNCAS_Pin;
  GPIO_InitStruct.Mode = GPIO_MODE_AF_PP;
  GPIO_InitStruct.Pull = GPIO_NOPULL;
  GPIO_InitStruct.Speed = GPIO_SPEED_FREQ_VERY_HIGH;
  GPIO_InitStruct.Alternate = GPIO_AF12_FMC;
  HAL_GPIO_Init(GPIOG, &GPIO_InitStruct);

  /*Configure GPIO pins : D4_Pin D5_Pin D6_Pin D7_Pin
                           D8_Pin D9_Pin D10_Pin D11_Pin
                           D12_Pin NBL0_Pin NBL1_Pin */
  GPIO_InitStruct.Pin = D4_Pin|D5_Pin|D6_Pin|D7_Pin
                          |D8_Pin|D9_Pin|D10_Pin|D11_Pin
                          |D12_Pin|NBL0_Pin|NBL1_Pin;
  GPIO_InitStruct.Mode = GPIO_MODE_AF_PP;
  GPIO_InitStruct.Pull = GPIO_NOPULL;
  GPIO_InitStruct.Speed = GPIO_SPEED_FREQ_VERY_HIGH;
  GPIO_InitStruct.Alternate = GPIO_AF12_FMC;
  HAL_GPIO_Init(GPIOE, &GPIO_InitStruct);

  /*Configure GPIO pins : G4_Pin G5_Pin B6_Pin B7_Pin */
  GPIO_InitStruct.Pin = G4_Pin|G5_Pin|B6_Pin|B7_Pin;
  GPIO_InitStruct.Mode = GPIO_MODE_AF_PP;
  GPIO_InitStruct.Pull = GPIO_NOPULL;
  GPIO_InitStruct.Speed = GPIO_SPEED_FREQ_LOW;
  GPIO_InitStruct.Alternate = GPIO_AF14_LTDC;
  HAL_GPIO_Init(GPIOB, &GPIO_InitStruct);

  /*Configure GPIO pins : D13_Pin D14_Pin D15_Pin D0_Pin
                           D1_Pin D2_Pin D3_Pin */
  GPIO_InitStruct.Pin = D13_Pin|D14_Pin|D15_Pin|D0_Pin
                          |D1_Pin|D2_Pin|D3_Pin;
  GPIO_InitStruct.Mode = GPIO_MODE_AF_PP;
  GPIO_InitStruct.Pull = GPIO_NOPULL;
  GPIO_InitStruct.Speed = GPIO_SPEED_FREQ_VERY_HIGH;
  GPIO_InitStruct.Alternate = GPIO_AF12_FMC;
  HAL_GPIO_Init(GPIOD, &GPIO_InitStruct);

  /*Configure GPIO pin : TE_Pin */
  GPIO_InitStruct.Pin = TE_Pin;
  GPIO_InitStruct.Mode = GPIO_MODE_INPUT;
  GPIO_InitStruct.Pull = GPIO_NOPULL;
  HAL_GPIO_Init(TE_GPIO_Port, &GPIO_InitStruct);

  /*Configure GPIO pins : RDX_Pin WRX_DCX_Pin */
  GPIO_InitStruct.Pin = RDX_Pin|WRX_DCX_Pin;
  GPIO_InitStruct.Mode = GPIO_MODE_OUTPUT_PP;
  GPIO_InitStruct.Pull = GPIO_NOPULL;
  GPIO_InitStruct.Speed = GPIO_SPEED_FREQ_LOW;
  HAL_GPIO_Init(GPIOD, &GPIO_InitStruct);

  /*Configure GPIO pins : R7_Pin DOTCLK_Pin B3_Pin */
  GPIO_InitStruct.Pin = R7_Pin|DOTCLK_Pin|B3_Pin;
  GPIO_InitStruct.Mode = GPIO_MODE_AF_PP;
  GPIO_InitStruct.Pull = GPIO_NOPULL;
  GPIO_InitStruct.Speed = GPIO_SPEED_FREQ_LOW;
  GPIO_InitStruct.Alternate = GPIO_AF14_LTDC;
  HAL_GPIO_Init(GPIOG, &GPIO_InitStruct);

  /*Configure GPIO pins : HSYNC_Pin G6_Pin R2_Pin */
  GPIO_InitStruct.Pin = HSYNC_Pin|G6_Pin|R2_Pin;
  GPIO_InitStruct.Mode = GPIO_MODE_AF_PP;
  GPIO_InitStruct.Pull = GPIO_NOPULL;
  GPIO_InitStruct.Speed = GPIO_SPEED_FREQ_LOW;
  GPIO_InitStruct.Alternate = GPIO_AF14_LTDC;
  HAL_GPIO_Init(GPIOC, &GPIO_InitStruct);

  /*Configure GPIO pin : I2C3_SDA_Pin */
  GPIO_InitStruct.Pin = I2C3_SDA_Pin;
  GPIO_InitStruct.Mode = GPIO_MODE_AF_OD;
  GPIO_InitStruct.Pull = GPIO_PULLUP;
  GPIO_InitStruct.Speed = GPIO_SPEED_FREQ_LOW;
  GPIO_InitStruct.Alternate = GPIO_AF4_I2C3;
  HAL_GPIO_Init(I2C3_SDA_GPIO_Port, &GPIO_InitStruct);

  /*Configure GPIO pin : I2C3_SCL_Pin */
  GPIO_InitStruct.Pin = I2C3_SCL_Pin;
  GPIO_InitStruct.Mode = GPIO_MODE_AF_OD;
  GPIO_InitStruct.Pull = GPIO_PULLUP;
  GPIO_InitStruct.Speed = GPIO_SPEED_FREQ_LOW;
  GPIO_InitStruct.Alternate = GPIO_AF4_I2C3;
  HAL_GPIO_Init(I2C3_SCL_GPIO_Port, &GPIO_InitStruct);

  /*Configure GPIO pins : G7_Pin B2_Pin */
  GPIO_InitStruct.Pin = G7_Pin|B2_Pin;
  GPIO_InitStruct.Mode = GPIO_MODE_AF_PP;
  GPIO_InitStruct.Pull = GPIO_NOPULL;
  GPIO_InitStruct.Speed = GPIO_SPEED_FREQ_LOW;
  GPIO_InitStruct.Alternate = GPIO_AF14_LTDC;
  HAL_GPIO_Init(GPIOD, &GPIO_InitStruct);

  /*Configure GPIO pins : G3_Pin B4_Pin */
  GPIO_InitStruct.Pin = G3_Pin|B4_Pin;
  GPIO_InitStruct.Mode = GPIO_MODE_AF_PP;
  GPIO_InitStruct.Pull = GPIO_NOPULL;
  GPIO_InitStruct.Speed = GPIO_SPEED_FREQ_LOW;
  GPIO_InitStruct.Alternate = GPIO_AF9_LTDC;
  HAL_GPIO_Init(GPIOG, &GPIO_InitStruct);

  /*Configure GPIO pins : LD3_Pin LD4_Pin */
  GPIO_InitStruct.Pin = LD3_Pin|LD4_Pin;
  GPIO_InitStruct.Mode = GPIO_MODE_OUTPUT_PP;
  GPIO_InitStruct.Pull = GPIO_NOPULL;
  GPIO_InitStruct.Speed = GPIO_SPEED_FREQ_LOW;
  HAL_GPIO_Init(GPIOG, &GPIO_InitStruct);

  /*Configure GPIO pins : SDCKE1_Pin SDNE1_Pin */
  GPIO_InitStruct.Pin = SDCKE1_Pin|SDNE1_Pin;
  GPIO_InitStruct.Mode = GPIO_MODE_AF_PP;
  GPIO_InitStruct.Pull = GPIO_NOPULL;
  GPIO_InitStruct.Speed = GPIO_SPEED_FREQ_VERY_HIGH;
  GPIO_InitStruct.Alternate = GPIO_AF12_FMC;
  HAL_GPIO_Init(GPIOB, &GPIO_InitStruct);

}

/* USER CODE BEGIN 4 */
//
//static int32_t PreCommunicateWithSPI0()
//
//{
//
//int32_t lRet = CIFX_NO_ERROR;
//
//uint8_t tx_data[10] = {0x01, 0x02, 0x03, 0x04, 0x05, 0x06, 0x07, 0x08, 0x09, 0x0A};
//
//uint8_t rx_data[10] = {0};
//
//printf("Starting SPI0 pre-communication with netX90...\r\n");
//
//// SPI0 통신 수행 (예시)
//
//HAL_GPIO_WritePin(GPIOA, GPIO_PIN_5, GPIO_PIN_SET); //
//HAL_GPIO_WritePin(GPIOA, GPIO_PIN_6, GPIO_PIN_RESET); // CS Low
//
//if(HAL_SPI_TransmitReceive(&hspi4, tx_data, rx_data, 10, 1000) != HAL_OK)
//
//{
//
//lRet = CIFX_FUNCTION_FAILED;
//
//printf("SPI0 communication failed\r\n");
//
//}
//
//else
//
//{
//
//printf("SPI0 communication successful\r\n");
//
//// 수신된 데이터 처리
//
//for(int i = 0; i < 10; i++)
//
//{
//
//printf("RX[%d]: 0x%02X\r\n", i, rx_data[i]);
//
//}
//
//}
//
//HAL_GPIO_WritePin(GPIOA, GPIO_PIN_6, GPIO_PIN_SET); // CS High
//
//return lRet;
//
//}

// 인터럽트 콜백
//void HAL_UART_RxCpltCallback(UART_HandleTypeDef *huart)
//{
//  if (huart->Instance == UART5)
//  {
//    rxReady = 1;
//  }
//}

// 에러 콜백
void HAL_UART_ErrorCallback(UART_HandleTypeDef *huart)
{
  if (huart->Instance == UART5)
  {
    // 에러 종류 확인 및 처리
    uint32_t error = HAL_UART_GetError(huart);

    HAL_UART_Transmit(&huart5, (uint8_t*)"UART Error Code: 0x", 19, HAL_MAX_DELAY);

    // 에러 코드를 16진수로 출력
    char errorStr[9];
    sprintf(errorStr, "%08X", (unsigned int)error);
    HAL_UART_Transmit(&huart5, (uint8_t*)errorStr, 8, HAL_MAX_DELAY);
    HAL_UART_Transmit(&huart5, (uint8_t*)"\r\n", 2, HAL_MAX_DELAY);

    // UART 상태 재설정 및 수신 재시작
    if(__HAL_UART_GET_FLAG(huart, UART_FLAG_ORE)) {
        __HAL_UART_CLEAR_OREFLAG(huart);
    }
    if(__HAL_UART_GET_FLAG(huart, UART_FLAG_NE)) {
        __HAL_UART_CLEAR_NEFLAG(huart);
    }
    if(__HAL_UART_GET_FLAG(huart, UART_FLAG_FE)) {
        __HAL_UART_CLEAR_FEFLAG(huart);
    }
    if(__HAL_UART_GET_FLAG(huart, UART_FLAG_PE)) {
        __HAL_UART_CLEAR_PEFLAG(huart);
    }

    // UART 수신 재시작
    HAL_UART_Receive_IT(huart, &rx_temp, 1);
  }
}

//
//static int32_t PreCommunicateWithSPI0()
//{
//    int32_t lRet = CIFX_NO_ERROR;
//    uint8_t tx_data[10] = {0x01, 0x02, 0x03, 0x04, 0x05, 0x06, 0x07, 0x08, 0x09, 0x0A};
////    uint8_t rx_data[10] = {0};
//    uint32_t success_count = 0;
//
//    printf("Starting SPI0 pre-communication with netX90 (20 attempts)...\r\n");
//
//    // 20회 반복
//    for(int attempt = 1; attempt <= 20; attempt++)
//    {
//        HAL_GPIO_WritePin(GPIOA, GPIO_PIN_6, GPIO_PIN_RESET); // CS Low
////        HAL_Delay(1);
//        for (volatile int i = 0; i < 1000; i++) __NOP();  // 약 100~150μs
//
//        if(HAL_SPI_TransmitReceive(&hspi4, tx_data, rx_data, 10, 1000) != HAL_OK)
//        {
//            printf("Attempt %d: FAILED\r\n", attempt);
//        }
//        else
//        {
//            printf("Attempt %d: SUCCESS\r\n", attempt);
//            success_count++;
//        }
//
//        HAL_GPIO_WritePin(GPIOA, GPIO_PIN_6, GPIO_PIN_SET); // CS High
//        HAL_Delay(100); // 100ms 대기
//    }
//
//    printf("Success: %lu/20 attempts\r\n", success_count);
//
//    if(success_count > 0)
//        lRet = CIFX_NO_ERROR;
//    else
//        lRet = CIFX_FUNCTION_FAILED;
//
//    return lRet;
//}

void UART_Ring_Init(UART_HandleTypeDef *huart)
{
    huart_ring = huart;
    rx_ring.head = 0;
    rx_ring.tail = 0;

    // 첫 1바이트 수신 시작
    HAL_UART_Receive_IT(huart_ring, &rx_temp, 1);
}

// 인터럽트 콜백: 수신 완료 시 호출됨
void HAL_UART_RxCpltCallback(UART_HandleTypeDef *huart)
{

	  if (huart->Instance == UART5)
	  {
	    rxReady = 1;
	  }

    if (huart == huart_ring)
    {
        uint16_t next_head = (rx_ring.head + 1) % UART_RX_BUFFER_SIZE;

        // 버퍼가 가득 차면 덮어쓰지 않음 (오버플로우 방지)
        if (next_head != rx_ring.tail)
        {
            rx_ring.buffer[rx_ring.head] = rx_temp;
            rx_ring.head = next_head;
        }

        // 다음 수신 요청
        HAL_UART_Receive_IT(huart_ring, &rx_temp, 1);
    }
}

// Ring buffer에서 1바이트 읽기
int UART_Ring_Read(uint8_t *data)
{
    if (rx_ring.head == rx_ring.tail)
    {
        return 0; // 데이터 없음
    }

    *data = rx_ring.buffer[rx_ring.tail];
    rx_ring.tail = (rx_ring.tail + 1) % UART_RX_BUFFER_SIZE;
    return 1;
}

// 수정된 부분: 라인 종결 문자를 '\r' (0x0D)로 변경
// 줄 단위 수신 (0x0D로 종료되는 문자열)
int UART_Ring_ReadLine(uint8_t *lineBuf, uint16_t maxLen)
{
    uint16_t i = 0;
    uint8_t ch;

    // Read from the ring buffer until a line is complete or buffer is empty
    while (i < maxLen - 1)
    {
        if (!UART_Ring_Read(&ch))
        {
            // No new character available yet, return 0 to signal no complete line
            return 0;
        }

        if (ch == '\r')
        {
            // Found the carriage return terminator
            lineBuf[i] = '\0'; // Replace \r with null terminator
            return i;
        }
        else
        {
            lineBuf[i++] = ch;
        }
    }

    // Buffer overflow or no terminator found within maxLen.
    lineBuf[i] = '\0';
    return i;
}

/*!
 * \brief Extract DIP switch data from received UART line
 * \param[in] line - Received UART line buffer
 * \param[out] dipData - Extracted 4-bit DIP switch data (as string)
 * \return 1 if valid DIP data found, 0 otherwise
 */
static uint8_t ExtractDipSwitchData(const uint8_t *line, uint8_t *dipData)
{
    // Look for pattern "D:[XXXX]" where XXXX is 4 binary digits
    const char *dipStart = strstr((const char*)line, "D:[");

    if (dipStart == NULL) {
        HAL_UART_Transmit(&huart5, (uint8_t *)"No D pattern found\r\n", 20, HAL_MAX_DELAY);
        return 0;
    }

    dipStart += 3; // Move to start of binary digits

    // Validate 4 binary digits
    for (int i = 0; i < 4; i++)
    {
        if (dipStart[i] != '0' && dipStart[i] != '1') {
            HAL_UART_Transmit(&huart5, (uint8_t *)"Invalid D digit at pos ", 23, HAL_MAX_DELAY);
            char posStr[2] = {'0' + i, '\0'};
            HAL_UART_Transmit(&huart5, (uint8_t *)posStr, 1, HAL_MAX_DELAY);
            HAL_UART_Transmit(&huart5, (uint8_t *)"\r\n", 2, HAL_MAX_DELAY);
            return 0;
        }
        dipData[i] = dipStart[i];
    }

    // Check for closing bracket
    if (dipStart[4] != ']') {
        HAL_UART_Transmit(&huart5, (uint8_t *)"Missing closing bracket\r\n", 25, HAL_MAX_DELAY);
        return 0;
    }

    dipData[4] = '\0'; // Null terminate

    HAL_UART_Transmit(&huart5, (uint8_t *)"D extracted: ", 13, HAL_MAX_DELAY);
    HAL_UART_Transmit(&huart5, dipData, 4, HAL_MAX_DELAY);
    HAL_UART_Transmit(&huart5, (uint8_t *)"\r\n", 2, HAL_MAX_DELAY);

    return 1;
}

/*!
 * \brief Validate D switch data with single reception
 * \param[in] currentLine - Current received UART line
 * \return 1 if validation successful, 0 if extraction failed
 */
static uint8_t ValidateDipSwitchData(const uint8_t *currentLine)
{
    uint8_t currentDipData[5] = {0};

    HAL_UART_Transmit(&huart5, (uint8_t *)"Validating line: ", 17, HAL_MAX_DELAY);
    HAL_UART_Transmit(&huart5, (uint8_t *)currentLine, strlen((const char*)currentLine), HAL_MAX_DELAY);
    HAL_UART_Transmit(&huart5, (uint8_t *)"\r\n", 2, HAL_MAX_DELAY);

    // Extract D data from current line
    if (ExtractDipSwitchData(currentLine, currentDipData) == 0) {
        HAL_UART_Transmit(&huart5, (uint8_t *)"D extraction failed\r\n", 21, HAL_MAX_DELAY);
        return 0; // No valid D data in current line
    }

    // Single reception validation - no comparison needed
    for(int i = 0; i < 5; i++) g_DipSwitchData[i] = currentDipData[i];
    g_bDipDataValid = 1;

    HAL_UART_Transmit(&huart5, (uint8_t *)"D validation SUCCESS: ", 22, HAL_MAX_DELAY);
    HAL_UART_Transmit(&huart5, (uint8_t*)g_DipSwitchData, 4, HAL_MAX_DELAY);
    HAL_UART_Transmit(&huart5, (uint8_t *)"\r\n", 2, HAL_MAX_DELAY);

    return 1; // Validation successful immediately
}

/* USER CODE END 4 */

void HAL_TIM_PeriodElapsedCallback(TIM_HandleTypeDef *htim)
{
  if (htim->Instance == TIM6) {
    HAL_IncTick();
  }
}

void Error_Handler(void)
{
  __disable_irq();
  while (1)
  {
  }
}
